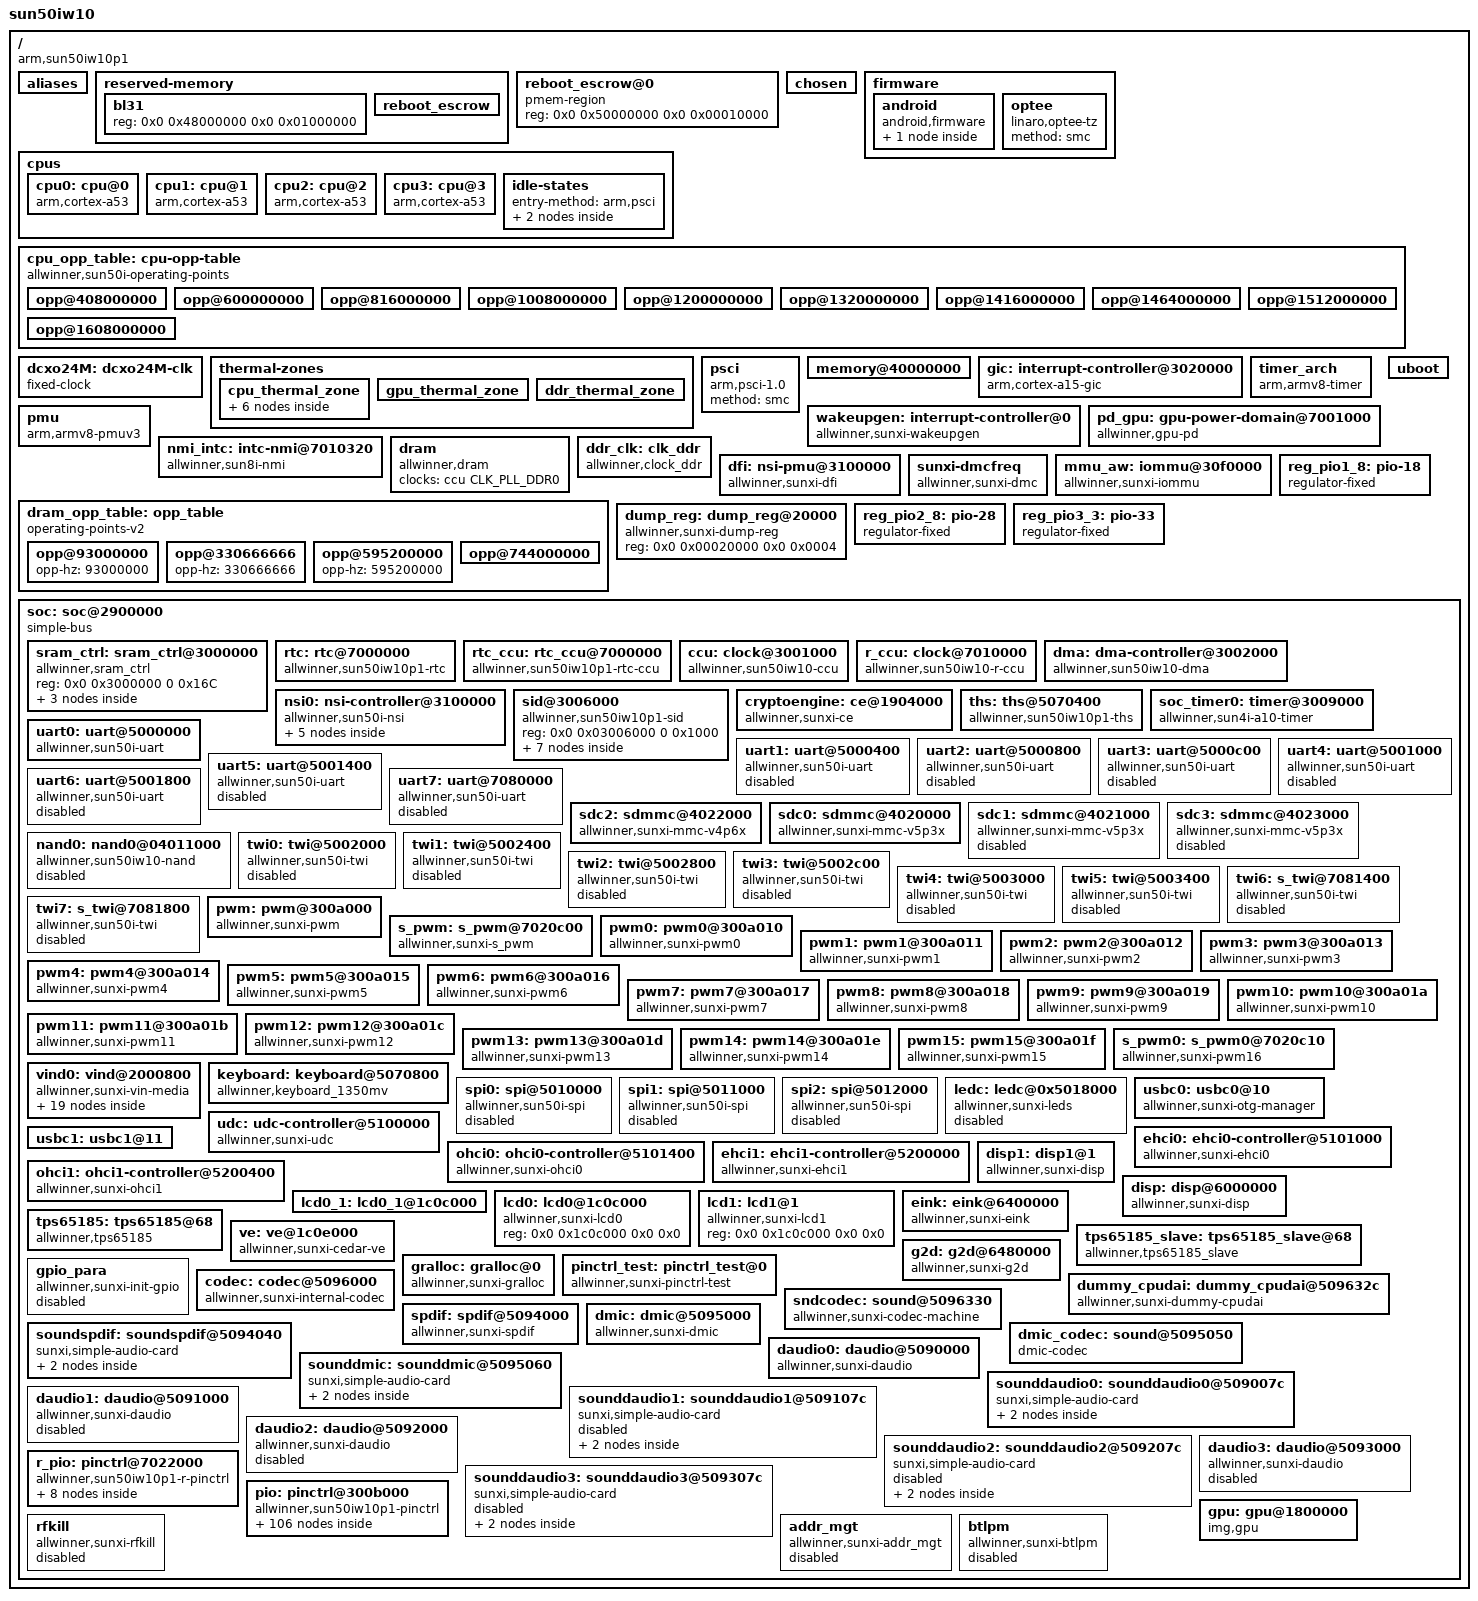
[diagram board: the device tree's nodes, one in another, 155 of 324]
/*
 * Allwinner Technology CO., Ltd. sun50iw10p1 platform
 *
 * modify base on juno.dts
 */

#include <dt-bindings/clock/sun50iw10-ccu.h>
#include <dt-bindings/clock/sun50iw10-r-ccu.h>
#include <dt-bindings/clock/sun50iw10-rtc.h>
#include <dt-bindings/gpio/gpio.h>
#include <dt-bindings/gpio/sun4i-gpio.h>
#include <dt-bindings/interrupt-controller/arm-gic.h>
#include <dt-bindings/reset/sun50iw10-ccu.h>
#include <dt-bindings/reset/sun50iw10-r-ccu.h>
#include <dt-bindings/thermal/thermal.h>

/ {
	model = "sun50iw10";
	compatible = "arm,sun50iw10p1";
	interrupt-parent = <&wakeupgen>;
	#address-cells = <2>;
	#size-cells = <2>;

	aliases {
		serial0 = &uart0;
		serial1 = &uart1;
		serial2 = &uart2;
		serial3 = &uart3;
		serial4 = &uart4;
		serial5 = &uart5;
		serial6 = &uart6;
		serial7 = &uart7;
		lcd0 = &lcd0;
		lcd1 = &lcd1;
		eink = &eink;
		mmc0 = &sdc0;
		mmc2 = &sdc2;
		nand0 =&nand0;
		twi0 = &twi0;
		twi1 = &twi1;
		twi2 = &twi2;
		twi3 = &twi3;
		twi4 = &twi4;
		twi5 = &twi5;
		twi6 = &twi6;
		twi7 = &twi7;
		spi0 = &spi0;
		spi1 = &spi1;
		spi2 = &spi2;
		ledc = &ledc;
		pwm = &pwm;
		s-pwm = &s_pwm;
		pwm0 = &pwm0;
		pwm1 = &pwm1;
		pwm2 = &pwm2;
		pwm3 = &pwm3;
		pwm4 = &pwm4;
		pwm5 = &pwm5;
		pwm6 = &pwm6;
		pwm7 = &pwm7;
		pwm8 = &pwm8;
		pwm9 = &pwm9;
		pwm10 = &pwm10;
		pwm11 = &pwm11;
		pwm12 = &pwm12;
		pwm13 = &pwm13;
		pwm14 = &pwm14;
		pwm15 = &pwm15;
		s-pwm0 = &s_pwm0;
		global-timer0  = &soc_timer0;
		tps65185 = &tps65185;
		tps65185-slave = &tps65185_slave;
	};

	reserved-memory {
		#address-cells = <2>;
		#size-cells = <2>;
		ranges;

		bl31 {
			reg = <0x0 0x48000000 0x0 0x01000000>;
		};
		reboot_escrow {
			no-map;
			reg = <0x0 0x50000000 0x0 0x10000>;
		};
	};

	reboot_escrow@0 {
		compatible = "pmem-region";
		reg = <0x0 0x50000000 0x0 0x00010000>;
	};

	chosen {
		bootargs = "earlyprintk=sunxi-uart,0x05000000 loglevel=8 initcall_debug=0 console=ttyS0 init=/init";
		linux,initrd-start = <0x0 0x0>;
		linux,initrd-end = <0x0 0x0>;
	};

	firmware {
		android {
			compatible = "android,firmware";
			name = "android";
			boot_devices = "soc@2900000/4020000.sdmmc,soc@2900000/4022000.sdmmc,soc@2900000";
			vbmeta {
				compatible = "android,vbmeta";
				parts = "vbmeta,vbmeta_system,vbmeta_vendor,boot";
			};
		};
		optee {
			compatible = "linaro,optee-tz";
			method = "smc";
		};
	};

	cpus {
		#address-cells = <2>;
		#size-cells = <0>;

		cpu0: cpu@0 {
			device_type = "cpu";
			compatible = "arm,cortex-a53","arm,armv8";
			reg = <0x0 0x0>;
			enable-method = "psci";
			clocks = <&ccu CLK_CPUX>;
			clock-latency = <2000000>;
			clock-frequency = <1320000000>;
			dynamic-power-coefficient = <190>;
			operating-points-v2 = <&cpu_opp_table>;
			cpu-idle-states = <&CPU_SLEEP_0 &CLUSTER_SLEEP_0>;
			#cooling-cells = <2>;
		};

		cpu1: cpu@1 {
			device_type = "cpu";
			compatible = "arm,cortex-a53","arm,armv8";
			reg = <0x0 0x1>;
			enable-method = "psci";
			clocks = <&ccu CLK_CPUX>;
			clock-frequency = <1320000000>;
			operating-points-v2 = <&cpu_opp_table>;
			cpu-idle-states = <&CPU_SLEEP_0 &CLUSTER_SLEEP_0>;
			#cooling-cells = <2>;
		};

		cpu2: cpu@2 {
			device_type = "cpu";
			compatible = "arm,cortex-a53","arm,armv8";
			reg = <0x0 0x2>;
			enable-method = "psci";
			clocks = <&ccu CLK_CPUX>;
			clock-frequency = <1320000000>;
			operating-points-v2 = <&cpu_opp_table>;
			cpu-idle-states = <&CPU_SLEEP_0 &CLUSTER_SLEEP_0>;
			#cooling-cells = <2>;
		};

		cpu3: cpu@3 {
			device_type = "cpu";
			compatible = "arm,cortex-a53","arm,armv8";
			reg = <0x0 0x3>;
			enable-method = "psci";
			clocks = <&ccu CLK_CPUX>;
			clock-frequency = <1320000000>;
			operating-points-v2 = <&cpu_opp_table>;
			cpu-idle-states = <&CPU_SLEEP_0 &CLUSTER_SLEEP_0>;
			#cooling-cells = <2>;
		};

		idle-states {
			entry-method = "arm,psci";

			CPU_SLEEP_0: cpu-sleep-0 {
				compatible = "arm,idle-state";
				arm,psci-suspend-param = <0x0010000>;
				entry-latency-us = <46>;
				exit-latency-us = <59>;
				min-residency-us = <3570>;
				local-timer-stop;
			};

			CLUSTER_SLEEP_0: cluster-sleep-0 {
				compatible = "arm,idle-state";
				arm,psci-suspend-param = <0x1010000>;
				entry-latency-us = <47>;
				exit-latency-us = <74>;
				min-residency-us = <5000>;
				local-timer-stop;
			};
		};
	};

	cpu_opp_table: cpu-opp-table {
		compatible = "allwinner,sun50i-operating-points";
		nvmem-cells = <&speedbin_efuse>, <&cpubin_efuse>, <&cpubin_extend>;
		nvmem-cell-names = "speed", "bin", "bin_ext";
		opp-shared;

		opp@408000000 {
			opp-hz = /bits/ 64 <408000000>;
			clock-latency-ns = <244144>; /* 8 32k periods */
			opp-microvolt-a0 = <900000>;
			opp-microvolt-a1 = <900000>;
			opp-microvolt-a2 = <900000>;
			opp-microvolt-a3 = <940000>;
			opp-microvolt-a4 = <940000>;
			opp-microvolt-a5 = <920000>;
			opp-microvolt-a6 = <920000>;
			opp-microvolt-b0 = <900000>;
			opp-microvolt-b1 = <900000>;
			opp-microvolt-b2 = <940000>;
			opp-microvolt-b3 = <920000>;
			opp-supported-hw = <0x7>;
		};

		opp@600000000 {
			opp-hz = /bits/ 64 <600000000>;
			clock-latency-ns = <244144>; /* 8 32k periods */
			opp-microvolt-a0 = <900000>;
			opp-microvolt-a1 = <900000>;
			opp-microvolt-a2 = <900000>;
			opp-microvolt-a3 = <940000>;
			opp-microvolt-a4 = <940000>;
			opp-microvolt-a5 = <920000>;
			opp-microvolt-a6 = <920000>;
			opp-microvolt-b0 = <900000>;
			opp-microvolt-b1 = <900000>;
			opp-microvolt-b2 = <940000>;
			opp-microvolt-b3 = <920000>;
			opp-supported-hw = <0x7>;
		};

		opp@816000000 {
			opp-hz = /bits/ 64 <816000000>;
			clock-latency-ns = <244144>; /* 8 32k periods */
			opp-microvolt-a0 = <940000>;
			opp-microvolt-a1 = <900000>;
			opp-microvolt-a2 = <900000>;
			opp-microvolt-a3 = <940000>;
			opp-microvolt-a4 = <940000>;
			opp-microvolt-a5 = <920000>;
			opp-microvolt-a6 = <920000>;
			opp-microvolt-b0 = <900000>;
			opp-microvolt-b1 = <900000>;
			opp-microvolt-b2 = <940000>;
			opp-microvolt-b3 = <920000>;
			opp-supported-hw = <0x7>;
		};

		opp@1008000000 {
			opp-hz = /bits/ 64 <1008000000>;
			clock-latency-ns = <244144>; /* 8 32k periods */
			opp-microvolt-a0 = <1020000>;
			opp-microvolt-a1 = <980000>;
			opp-microvolt-a2 = <950000>;
			opp-microvolt-a3 = <1020000>;
			opp-microvolt-a4 = <960000>;
			opp-microvolt-a5 = <940000>;
			opp-microvolt-a6 = <940000>;
			opp-microvolt-b0 = <980000>;
			opp-microvolt-b1 = <950000>;
			opp-microvolt-b2 = <960000>;
			opp-microvolt-b3 = <940000>;
			opp-supported-hw = <0x7>;
		};

		opp@1200000000 {
			opp-hz = /bits/ 64 <1200000000>;
			clock-latency-ns = <244144>; /* 8 32k periods */
			opp-microvolt-a0 = <1100000>;
			opp-microvolt-a1 = <1020000>;
			opp-microvolt-a2 = <1000000>;
			opp-microvolt-a3 = <1100000>;
			opp-microvolt-a4 = <980000>;
			opp-microvolt-a5 = <960000>;
			opp-microvolt-a6 = <960000>;
			opp-microvolt-b0 = <1020000>;
			opp-microvolt-b1 = <1000000>;
			opp-microvolt-b2 = <980000>;
			opp-microvolt-b3 = <960000>;
			opp-supported-hw = <0x7>;
		};

		opp@1320000000 {
			opp-hz = /bits/ 64 <1320000000>;
			clock-latency-ns = <244144>; /* 8 32k periods */
			opp-microvolt-a0 = <1160000>;
			opp-microvolt-a1 = <1060000>;
			opp-microvolt-a2 = <1030000>;
			opp-microvolt-a3 = <1160000>;
			opp-microvolt-a4 = <1020000>;
			opp-microvolt-a5 = <1000000>;
			opp-microvolt-a6 = <1000000>;
			opp-microvolt-b0 = <1060000>;
			opp-microvolt-b1 = <1030000>;
			opp-microvolt-b2 = <1020000>;
			opp-microvolt-b3 = <1000000>;
			opp-supported-hw = <0x7>;
		};

		opp@1416000000 {
			opp-hz = /bits/ 64 <1416000000>;
			clock-latency-ns = <244144>; /* 8 32k periods */
			opp-microvolt-b0 = <1100000>;
			opp-microvolt-b1 = <1070000>;
			opp-microvolt-b2 = <1060000>;
			opp-microvolt-b3 = <1040000>;
			opp-supported-hw = <0x6>;
		};

		opp@1464000000 {
			opp-hz = /bits/ 64 <1464000000>;
			clock-latency-ns = <244144>; /* 8 32k periods */
			opp-microvolt-a0 = <1180000>;
			opp-microvolt-a1 = <1180000>;
			opp-microvolt-a2 = <1130000>;
			opp-microvolt-a3 = <1180000>;
			opp-microvolt-a4 = <1100000>;
			opp-microvolt-a5 = <1080000>;
			opp-microvolt-a6 = <1080000>;
			opp-supported-hw = <0x1>;
		};

		opp@1512000000 {
			opp-hz = /bits/ 64 <1512000000>;
			clock-latency-ns = <244144>; /* 8 32k periods */
			opp-microvolt-b0 = <1180000>;
			opp-microvolt-b1 = <1130000 1130000 1140000>;
			opp-microvolt-b2 = <1100000>;
			opp-microvolt-b3 = <1080000>;
			opp-supported-hw = <0x6>;
		};

		opp@1608000000 {
			opp-hz = /bits/ 64 <1608000000>;
			clock-latency-ns = <244144>; /* 8 32k periods */
			opp-microvolt-b0 = <1180000>;
			opp-microvolt-b1 = <1130000 1130000 1140000>;
			opp-supported-hw = <0x0>;
		};
	};

	dcxo24M: dcxo24M-clk {
		#clock-cells = <0>;
		compatible = "fixed-clock";
		clock-frequency = <24000000>;
		clock-output-names = "dcxo24M";
	};

	thermal-zones {
		cpu_thermal_zone {
			polling-delay-passive = <500>;
			polling-delay = <1000>;
			thermal-sensors = <&ths 0>;
			sustainable-power = <1200>;

			cpu_trips: trips {
				cpu_threshold: trip-point@0 {
					temperature = <70000>;
					type = "passive";
					hysteresis = <0>;
				};
				cpu_target: trip-point@1 {
					temperature = <90000>;
					type = "passive";
					hysteresis = <0>;
				};
				cpu_crit: cpu_crit@0 {
					temperature = <110000>;
					type = "critical";
					hysteresis = <0>;
				};
			};

			cooling-maps {
				map0 {
					trip = <&cpu_target>;
					cooling-device = <&cpu0
					THERMAL_NO_LIMIT
					THERMAL_NO_LIMIT>;
					contribution = <1024>;
				};
			};
		};
		gpu_thermal_zone{
			polling-delay-passive = <500>;
			polling-delay = <1000>;
			thermal-sensors = <&ths 1>;
			sustainable-power = <1100>;
		};
		ddr_thermal_zone{
			polling-delay-passive = <0>;
			polling-delay = <0>;
			thermal-sensors = <&ths 2>;
		};
	};

	psci {
		compatible = "arm,psci-1.0";
		method = "smc";
	};

	memory@40000000 {
		device_type = "memory";
		reg = <0x00000000 0x40000000 0x00000000 0x20000000>;
	};

	gic: interrupt-controller@3020000 {
		compatible = "arm,cortex-a15-gic", "arm,cortex-a9-gic";
		#interrupt-cells = <3>;
		#address-cells = <0>;
		device_type = "gic";
		interrupt-controller;
		reg = <0x0 0x03021000 0 0x1000>, /* GIC Dist */
		      <0x0 0x03022000 0 0x2000>, /* GIC CPU */
		      <0x0 0x03024000 0 0x2000>, /* GIC VCPU Control */
		      <0x0 0x03026000 0 0x2000>; /* GIC VCPU */
		interrupts = <GIC_PPI 9 0xf04>;  /* GIC Maintenence IRQ */
		interrupt-parent = <&gic>;
	};

	wakeupgen: interrupt-controller@0 {
		compatible = "allwinner,sunxi-wakeupgen";
		interrupt-controller;
		#interrupt-cells = <3>;
		interrupt-parent = <&gic>;
	};

	timer_arch {
		compatible = "arm,armv8-timer";
		interrupts = <GIC_PPI 13 (GIC_CPU_MASK_SIMPLE(4) | IRQ_TYPE_LEVEL_LOW)>,
			   <GIC_PPI 14 (GIC_CPU_MASK_SIMPLE(4) | IRQ_TYPE_LEVEL_LOW)>,
			   <GIC_PPI 11 (GIC_CPU_MASK_SIMPLE(4) | IRQ_TYPE_LEVEL_LOW)>,
			   <GIC_PPI 10 (GIC_CPU_MASK_SIMPLE(4) | IRQ_TYPE_LEVEL_LOW)>;
		clock-frequency = <24000000>;
		interrupt-parent = <&gic>;
		arm,no-tick-in-suspend;
	};

	pmu {
		compatible = "arm,armv8-pmuv3";
		interrupts = <GIC_SPI 140 IRQ_TYPE_LEVEL_HIGH>,
			     <GIC_SPI 141 IRQ_TYPE_LEVEL_HIGH>,
			     <GIC_SPI 142 IRQ_TYPE_LEVEL_HIGH>,
			     <GIC_SPI 143 IRQ_TYPE_LEVEL_HIGH>;
		interrupt-affinity = <&cpu0>, <&cpu1>, <&cpu2>, <&cpu3>;
	};

	pd_gpu: gpu-power-domain@7001000 {
		   compatible = "allwinner,gpu-pd", "syscon";
		   reg = <0x0 0x07001000 0x0 0x40>;
		   interrupts = <GIC_SPI 119 IRQ_TYPE_LEVEL_HIGH>;
		   interrupt-names = "ppu-irq";
		   clocks = <&r_ccu CLK_R_APB1_PPU>;
		   clock-names = "ppu";
		   resets = <&r_ccu RST_R_APB1_PPU>;
		   reset-names = "ppu_rst";
		   #power-domain-cells = <0>;
	};

	nmi_intc: intc-nmi@7010320 {
		compatible = "allwinner,sun8i-nmi";
		interrupt-parent = <&gic>;
		#interrupt-cells = <2>;
		#address-cells = <0>;
		interrupt-controller;
		reg = <0x0 0x07010320 0 0xc>;
		interrupts = <GIC_SPI 103 IRQ_TYPE_LEVEL_HIGH>;
	};

	dram: dram {
		compatible = "allwinner,dram";
		clocks = <&ccu CLK_PLL_DDR0>;
		clock-names = "pll_ddr";
	};

	ddr_clk: clk_ddr {
		compatible = "allwinner,clock_ddr";
		reg = <0x0 0x03001000 0x0 0x1000>, /*  */
			  <0x0 0x04810000 0x0 0x2000>;
		clocks = <&ccu CLK_PLL_DDR0>;
		clock-names = "pll_ddr";
		#clock-cells = <0>;
	};

	dfi: nsi-pmu@3100000 {
		compatible = "allwinner,sunxi-dfi", "syscon";
		reg = <0x0 0x03100000 0x0 0x10000>;
		clocks = <&ddr_clk>;
		clock-names = "dram";
	};

	dram_opp_table: opp_table {
		compatible = "operating-points-v2";

		opp@93000000 {
			opp-hz = /bits/ 64 <93000000>;
		};
		opp@330666666 {
			opp-hz = /bits/ 64 <330666666>;
		};
		opp@595200000 {
			opp-hz = /bits/ 64 <595200000>;
		};
		opp@744000000 {
			opp-hz = /bits/ 64 <744000000>;
			opp-suspend;
		};
	};

	sunxi-dmcfreq {
		compatible = "allwinner,sunxi-dmc";
		devfreq-events = <&dfi>;
		clocks = <&ddr_clk>;
		clock-names = "dram";
		operating-points-v2 = <&dram_opp_table>;
		upthreshold = <60>;
		downdifferential = <20>;
	};

	uboot: uboot {
	};

	mmu_aw: iommu@30f0000 {
		compatible = "allwinner,sunxi-iommu";
		reg = <0x0 0x030f0000 0x0 0x1000>;
		interrupts = <GIC_SPI 66 IRQ_TYPE_LEVEL_HIGH>;
		interrupt-names = "iommu-irq";
		clocks = <&ccu CLK_BUS_IOMMU>;
		clock-names = "iommu";
		/* clock-frequency = <24000000>; */
		#iommu-cells = <2>;
	};

	dump_reg: dump_reg@20000 {
		compatible = "allwinner,sunxi-dump-reg";
		reg = <0x0 0x00020000 0x0 0x0004>;
		/* 0x00020000 is the addr for test, 0x0004 is the size for test */
	};

	reg_pio1_8: pio-18 {
		compatible = "regulator-fixed";
		regulator-name = "pio-18";
		regulator-min-microvolt = <1800000>;
		regulator-max-microvolt = <1800000>;
	};

	reg_pio2_8: pio-28 {
		compatible = "regulator-fixed";
		regulator-name = "pio-28";
		regulator-min-microvolt = <2800000>;
		regulator-max-microvolt = <2800000>;
	};

	reg_pio3_3: pio-33 {
		compatible = "regulator-fixed";
		regulator-name = "pio-33";
		regulator-min-microvolt = <3300000>;
		regulator-max-microvolt = <3300000>;
	};

	soc: soc@2900000 {
		compatible = "simple-bus";
		#address-cells = <2>;
		#size-cells = <2>;
		ranges;
		device_type = "soc";

		sram_ctrl: sram_ctrl@3000000 {
			compatible = "allwinner,sram_ctrl";
			reg = <0x0 0x3000000 0 0x16C>;
			soc_ver {
				offset = <0x24>;
				mask = <0x7>;
				shift = <0>;
				ver_a = <0x18550000>;
				ver_b = <0x18550001>;
			};

			soc_id {
				offset = <0x200>;
				mask = <0x1>;
				shift = <22>;
			};

			soc_bin {
				offset = <0x0>;
				mask = <0x3ff>;
				shift = <0x0>;
			};

		};

		rtc: rtc@7000000 {
			compatible = "allwinner,sun50iw10p1-rtc";
			device_type = "rtc";
			wakeup-source;
			reg = <0x0 0x07000000 0x0 0x200>;
			interrupts = <GIC_SPI 108 IRQ_TYPE_LEVEL_HIGH>;
			clocks = <&r_ccu CLK_R_AHB_BUS_RTC>, <&rtc_ccu CLK_RTC_1K>;
			clock-names = "r-ahb-rtc", "rtc-1k";
			resets = <&r_ccu RST_R_AHB_BUS_RTC>;
			gpr_offset = <0x100>;
			gpr_len = <8>;
			gpr_cur_pos = <6>;
		};

		rtc_ccu: rtc_ccu@7000000 {
			compatible = "allwinner,sun50iw10p1-rtc-ccu";
			device_type = "rtc-ccu";
			reg = <0x0 0x07000000 0x0 0x200>;
			#clock-cells = <1>;
			clock-output-names = "dcxo24M-out", "iosc", "osc32k",
					     "osc32k-out", "rtc-1k";
		};
		ccu: clock@3001000 {
			compatible = "allwinner,sun50iw10-ccu";
			reg = <0x0 0x03001000 0x0 0x1000>;
			clocks = <&dcxo24M>, <&rtc_ccu CLK_OSC32K>,
				 <&rtc_ccu CLK_IOSC>;
			clock-names = "hosc", "losc", "iosc";
			#clock-cells = <1>;
			#reset-cells = <1>;
		};

		r_ccu: clock@7010000 {
			compatible = "allwinner,sun50iw10-r-ccu";
			reg = <0x0 0x07010000 0x0 0x240>;
			clocks = <&dcxo24M>, <&rtc_ccu CLK_OSC32K>,
				 <&rtc_ccu CLK_IOSC>, <&ccu CLK_PLL_PERIPH0>;
			clock-names = "hosc", "losc", "iosc", "pll-periph";
			#clock-cells = <1>;
			#reset-cells = <1>;
		};

		dma: dma-controller@3002000 {
			compatible = "allwinner,sun50iw10-dma";
			reg = <0x0 0x03002000 0x0 0x1000>;
			interrupts = <GIC_SPI 45 IRQ_TYPE_LEVEL_HIGH>;
			clocks = <&ccu CLK_BUS_DMA>, <&ccu CLK_MBUS_DMA>;
			clock-names = "bus", "mbus";
			dma-channels = <8>;
			dma-requests = <52>;
			resets = <&ccu RST_BUS_DMA>;
			#dma-cells = <1>;
		};

		nsi0:nsi-controller@3100000 {
			compatible = "allwinner,sun50i-nsi";
			interrupts = <GIC_SPI 63 IRQ_TYPE_LEVEL_HIGH>;
			reg = <0x0 0x03100000 0x0 0x10000>;
			clocks = <&ccu CLK_PLL_DDR0>, <&ccu CLK_MBUS>, <&ddr_clk>;
			clock-names = "pll", "bus", "sdram";
			resets = <&ccu RST_MBUS>;
			clock-frequency = <372000000>;
			#nsi-cells = <1>;
			cpu{
				mode = <0>; /*dont't set cpu mode*/
				pri = <0>;
				select = <0>;
			};
			gpu{
				mode = <0>;
				pri = <3>;
				select = <1>;
			};
			sd1{
				mode = <1>;
				pri = <2>;
				select = <0>;
			};
			mstg{
				mode = <0>;
				pri = <1>;
				select = <0>;
			};
			ce{
				mode = <1>;
				pri = <0>;
				select = <1>;
			};
		};

		sid@3006000 {
			compatible = "allwinner,sun50iw10p1-sid", "allwinner,sunxi-sid";
			reg = <0x0 0x03006000 0 0x1000>;
			#address-cells = <1>;
			#size-cells = <1>;

			speedbin_efuse: speed@00 {
				reg = <0x0 2>;
			};

			ths_calib: calib@14 {
				reg = <0x14 8>;
			};

			cpubin_efuse: calib@1c {
				reg = <0x1c 2>;
			};

			cpubin_extend: calib@28 {
				reg = <0x28 4>;
			};

			/* some guys has nothing to do with nvmem */
			secure_status {
				reg = <0x0 0>;
				offset = <0xa0>;
				size = <0x4>;
			};
			chipid {
				reg = <0x0 0>;
				offset = <0x200>;
				size = <0x10>;
			};
			rotpk {
				reg = <0x0 0>;
				offset = <0x270>;
				size = <0x20>;
			};
		};

		cryptoengine: ce@1904000 {
			compatible = "allwinner,sunxi-ce";
			device_name = "ce";
			reg = <0x0 0x01904000 0x0 0xa0>, /* non-secure space */
			      <0x0 0x01904800 0x0 0xa0>; /* secure space */
			interrupts = <GIC_SPI 92 IRQ_TYPE_EDGE_RISING>, /*non-secure*/
				   <GIC_SPI 93 IRQ_TYPE_EDGE_RISING>; /* secure*/
			clock-frequency = <400000000>; /* 400MHz */
			clocks = <&ccu CLK_BUS_CE>, <&ccu CLK_CE>, <&ccu CLK_MBUS_CE>,
					<&ccu CLK_PLL_PERIPH0_2X>;
			clock-names = "bus_ce", "ce_clk", "mbus_ce", "pll_periph0_2x";
			resets = <&ccu RST_BUS_CE>;
		};

		ths: ths@5070400 {
			compatible = "allwinner,sun50iw10p1-ths";
			reg = <0x0 0x05070400 0x0 0x400>;
			clocks = <&ccu CLK_BUS_THS>;
			clock-names = "bus";
			resets = <&ccu RST_BUS_THS>;
			nvmem-cells = <&ths_calib>;
			nvmem-cell-names = "calibration";
			#thermal-sensor-cells = <1>;
		};

		soc_timer0: timer@3009000 {
			compatible = "allwinner,sun4i-a10-timer";
			device_type = "soc_timer";
			reg = <0x0 0x03009000 0x0 0xA0>;
			interrupt-parent = <&gic>;
			interrupts = <GIC_SPI 51 IRQ_TYPE_LEVEL_HIGH>;
			clocks = <&dcxo24M>;
		};

		uart0: uart@5000000 {
			compatible = "allwinner,sun50i-uart";
			device_type = "uart0";
			reg = <0x0 0x05000000 0x0 0x400>;
			interrupts = <GIC_SPI 0 IRQ_TYPE_LEVEL_HIGH>;
			sunxi,uart-fifosize = <64>;
			clocks = <&ccu CLK_BUS_UART0>;
			clock-names = "uart0";
			resets = <&ccu RST_BUS_UART0>;
			pinctrl-names = "default", "sleep";
			pinctrl-0 = <&uart0_pins_a>;
			pinctrl-1 = <&uart0_pins_b>;
			uart0_port = <0>;
			uart0_type = <2>;
			//dmas = <&dma 14>;
			//dma-names = "tx";
			//use_dma = <0>;
		};

		uart1: uart@5000400 {
			compatible = "allwinner,sun50i-uart";
			device_type = "uart1";
			reg = <0x0 0x05000400 0x0 0x400>;
			interrupts = <GIC_SPI 1 IRQ_TYPE_LEVEL_HIGH>;
			sunxi,uart-fifosize = <64>;
			clocks = <&ccu CLK_BUS_UART1>;
			clock-names = "uart1";
			resets = <&ccu RST_BUS_UART1>;
			pinctrl-names = "default", "sleep";
			pinctrl-0 = <&uart1_pins_a>;
			pinctrl-1 = <&uart1_pins_b>;
			uart1_port = <1>;
			uart1_type = <4>;
			status = "disabled";
		};

		uart2: uart@5000800 {
			compatible = "allwinner,sun50i-uart";
			device_type = "uart2";
			reg = <0x0 0x05000800 0x0 0x400>;
			interrupts = <GIC_SPI 2 IRQ_TYPE_LEVEL_HIGH>;
			sunxi,uart-fifosize = <64>;
			clocks = <&ccu CLK_BUS_UART2>;
			clock-names = "uart2";
			resets = <&ccu RST_BUS_UART2>;
			pinctrl-names = "default", "sleep";
			pinctrl-0 = <&uart2_pins_a>;
			pinctrl-1 = <&uart2_pins_b>;
			uart2_port = <2>;
			uart2_type = <4>;
			status = "disabled";
		};

		uart3: uart@5000c00 {
			compatible = "allwinner,sun50i-uart";
			device_type = "uart3";
			reg = <0x0 0x05000c00 0x0 0x400>;
			interrupts = <GIC_SPI 3 IRQ_TYPE_LEVEL_HIGH>;
			sunxi,uart-fifosize = <64>;
			clocks = <&ccu CLK_BUS_UART3>;
			clock-names = "uart3";
			resets = <&ccu RST_BUS_UART3>;
			pinctrl-names = "default", "sleep";
			pinctrl-0 = <&uart3_pins_a>;
			pinctrl-1 = <&uart3_pins_b>;
			uart3_port = <3>;
			uart3_type = <4>;
			status = "disabled";
		};

		uart4: uart@5001000 {
			compatible = "allwinner,sun50i-uart";
			device_type = "uart4";
			reg = <0x0 0x05001000 0x0 0x400>;
			interrupts = <GIC_SPI 4 IRQ_TYPE_LEVEL_HIGH>;
			clocks = <&ccu CLK_BUS_UART4>;
			clock-names = "uart4";
			resets = <&ccu RST_BUS_UART4>;
			sunxi,uart-fifosize = <64>;
			pinctrl-names = "default", "sleep";
			pinctrl-0 = <&uart4_pins_a>;
			pinctrl-1 = <&uart4_pins_b>;
			uart4_port = <4>;
			uart4_type = <4>;
			status = "disabled";
		};

		uart5: uart@5001400 {
			compatible = "allwinner,sun50i-uart";
			device_type = "uart5";
			reg = <0x0 0x05001400 0x0 0x400>;
			interrupts = <GIC_SPI 5 IRQ_TYPE_LEVEL_HIGH>;
			sunxi,uart-fifosize = <64>;
			clocks = <&ccu CLK_BUS_UART5>;
			clock-names = "uart5";
			resets = <&ccu RST_BUS_UART5>;
			pinctrl-names = "default", "sleep";
			pinctrl-0 = <&uart5_pins_a>;
			pinctrl-1 = <&uart5_pins_b>;
			uart5_port = <5>;
			uart5_type = <4>;
			status = "disabled";
		};

		uart6: uart@5001800 {
			compatible = "allwinner,sun50i-uart";
			device_type = "uart6";
			reg = <0x0 0x05001800 0x0 0x400>;
			interrupts = <GIC_SPI 6 IRQ_TYPE_LEVEL_HIGH>;
			sunxi,uart-fifosize = <64>;
			/* fix me */
			/*clocks = <&ccu CLK_BUS_UART6>;
			clock-names = "uart6";
			resets = <&ccu RST_BUS_UART6>;*/
			pinctrl-names = "default", "sleep";
			pinctrl-0 = <&uart6_pins_a>;
			pinctrl-1 = <&uart6_pins_b>;
			uart6_port = <6>;
			uart6_type = <4>;
			status = "disabled";
		};

		uart7: uart@7080000 {
			compatible = "allwinner,sun50i-uart";
			device_type = "uart7";
			reg = <0x0 0x07080000 0x0 0x400>;
			interrupts = <GIC_SPI 112 IRQ_TYPE_LEVEL_HIGH>;
			sunxi,uart-fifosize = <64>;
			/* fix me */
			/*clocks = <&r_ccu CLK_BUS_UART0>;
			clock-names = "uart7";
			resets = <&r_ccu RST_BUS_UART0>;*/
			pinctrl-names = "default", "sleep";
			pinctrl-0 = <&s_uart0_pins_a>;
			pinctrl-1 = <&s_uart0_pins_b>;
			uart7_port = <7>;
			uart7_type = <2>;
			status = "disabled";
		};

		sdc2: sdmmc@4022000 {
			compatible = "allwinner,sunxi-mmc-v4p6x";
			device_type = "sdc2";
			reg = <0x0 0x04022000 0x0 0x1000>;
			interrupts = <GIC_SPI 41 IRQ_TYPE_LEVEL_HIGH>;
			clocks = <&dcxo24M>,
				 <&ccu CLK_PLL_PERIPH1_2X>,
				 <&ccu CLK_MMC2>,
				 <&ccu CLK_BUS_MMC2>;
			clock-names = "osc24m","pll_periph","mmc","ahb";
			resets = <&ccu RST_BUS_MMC2>;
			reset-names = "rst";
			pinctrl-names = "default","sleep";
			pinctrl-0 = <&sdc2_pins_a &sdc2_pins_c>;
			pinctrl-1 = <&sdc2_pins_b>;
			bus-width = <8>;
			req-page-count = <2>;
			cap-mmc-highspeed;
			cap-cmd23;
			mmc-cache-ctrl;
			non-removable;
			/*max-frequency = <200000000>;*/
			max-frequency = <50000000>;
			cap-erase;
			mmc-high-capacity-erase-size;
			no-sdio;
			no-sd;
			/*-- speed mode --*/
			/*sm0: DS26_SDR12*/
			/*sm1: HSSDR52_SDR25*/
			/*sm2: HSDDR52_DDR50*/
			/*sm3: HS200_SDR104*/
			/*sm4: HS400*/
			/*-- frequency point --*/
			/*f0: CLK_400K*/
			/*f1: CLK_25M*/
			/*f2: CLK_50M*/
			/*f3: CLK_100M*/
			/*f4: CLK_150M*/
			/*f5: CLK_200M*/

			sdc_tm4_sm0_freq0 = <0>;
			sdc_tm4_sm0_freq1 = <0>;
			sdc_tm4_sm1_freq0 = <0x00000000>;
			sdc_tm4_sm1_freq1 = <0>;
			sdc_tm4_sm2_freq0 = <0x00000000>;
			sdc_tm4_sm2_freq1 = <0>;
			sdc_tm4_sm3_freq0 = <0x05000000>;
			sdc_tm4_sm3_freq1 = <0x00000005>;
			sdc_tm4_sm4_freq0 = <0x00050000>;
			sdc_tm4_sm4_freq1 = <0x00000004>;
			sdc_tm4_sm4_freq0_cmd = <0>;
			sdc_tm4_sm4_freq1_cmd = <0>;

			/*vmmc-supply = <&reg_3p3v>;*/
			/*vqmc-supply = <&reg_3p3v>;*/
			/*vdmc-supply = <&reg_3p3v>;*/
			/*vmmc = "vcc-card";*/
			/*vqmc = "";*/
			/*vdmc = "";*/
			/*sunxi-power-save-mode;*/
		};

		sdc0: sdmmc@4020000 {
			compatible = "allwinner,sunxi-mmc-v5p3x";
			device_type = "sdc0";
			reg = <0x0 0x04020000 0x0 0x1000>;
			interrupts = <GIC_SPI 39 IRQ_TYPE_LEVEL_HIGH>;
			clocks = <&dcxo24M>,
				 <&ccu CLK_PLL_PERIPH1_2X>,
				 <&ccu CLK_MMC0>,
				 <&ccu CLK_BUS_MMC0>;
			clock-names = "osc24m","pll_periph","mmc","ahb";
			resets = <&ccu RST_BUS_MMC0>;
			reset-names = "rst";
			pinctrl-names = "default","mmc_1v8","sleep","uart_jtag";
			pinctrl-0 = <&sdc0_pins_a>;
			pinctrl-1 = <&sdc0_pins_b>;
			pinctrl-2 = <&sdc0_pins_c>;
			pinctrl-3 = <&sdc0_pins_d &sdc0_pins_e>;
			max-frequency = <50000000>;
			bus-width = <4>;
			req-page-count = <2>;
			/*non-removable;*/
			/*broken-cd;*/
			/*cd-inverted*/
			/*cd-gpios = <&pio PF 6 GPIO_ACTIVE_LOW>;*/
			/* vmmc-supply = <&reg_3p3v>;*/
			/* vqmc-supply = <&reg_3p3v>;*/
			/* vdmc-supply = <&reg_3p3v>;*/
			/*vmmc = "vcc-card";*/
			/*vqmc = "";*/
			/*vdmc = "";*/
			cap-sd-highspeed;
			cap-wait-while-busy;
			no-sdio;
			no-mmc;
			/*sd-uhs-sdr50;*/
			/*sd-uhs-ddr50;*/
			/*cap-sdio-irq;*/
			/*keep-power-in-suspend;*/
			/*ignore-pm-notify;*/
			/*sunxi-power-save-mode;*/
			/*sunxi-dly-400k = <1 0 0 0>; */
			/*sunxi-dly-26M  = <1 0 0 0>;*/
			/*sunxi-dly-52M  = <1 0 0 0>;*/
			/*sunxi-dly-52M-ddr4  = <1 0 0 0>;*/
			/*sunxi-dly-52M-ddr8  = <1 0 0 0>;*/
			/*sunxi-dly-104M  = <1 0 0 0>;*/
			/*sunxi-dly-208M  = <1 0 0 0>;*/
			/*sunxi-dly-104M-ddr  = <1 0 0 0>;*/
			/*sunxi-dly-208M-ddr  = <1 0 0 0>;*/
		};

		sdc1: sdmmc@4021000 {
			compatible = "allwinner,sunxi-mmc-v5p3x";
			device_type = "sdc1";
			reg = <0x0 0x04021000 0x0 0x1000>;
			interrupts = <GIC_SPI 40 IRQ_TYPE_LEVEL_HIGH>;
			clocks = <&dcxo24M>,
				 <&ccu CLK_PLL_PERIPH1_2X>,
				 <&ccu CLK_MMC1>,
				 <&ccu CLK_BUS_MMC1>;
			clock-names = "osc24m","pll_periph","mmc","ahb";
			resets = <&ccu RST_BUS_MMC1>;
			reset-names = "rst";
			pinctrl-names = "default","sleep";
			pinctrl-0 = <&sdc1_pins_a>;
			pinctrl-1 = <&sdc1_pins_b>;
			max-frequency = <50000000>;
			bus-width = <4>;
			/*broken-cd;*/
			/*cd-inverted*/
			/*cd-gpios = <&pio PG 6 6 1 2 0>;*/
			/* vmmc-supply = <&reg_3p3v>;*/
			/* vqmc-supply = <&reg_3p3v>;*/
			/* vdmc-supply = <&reg_3p3v>;*/
			/*vmmc = "vcc-card";*/
			/*vqmc = "";*/
			/*vdmc = "";*/
			cap-sd-highspeed;
			no-mmc;
			/*sd-uhs-sdr50;*/
			/*sd-uhs-ddr50;*/
			/*sd-uhs-sdr104;*/
			/*cap-sdio-irq;*/
			keep-power-in-suspend;
			/*ignore-pm-notify;*/
			/*sunxi-power-save-mode;*/
			/*sunxi-dly-400k = <1 0 0 0 0>; */
			/*sunxi-dly-26M  = <1 0 0 0 0>;*/
			/*sunxi-dly-52M  = <1 0 0 0 0>;*/
			sunxi-dly-52M-ddr4  = <1 0 0 0 2>;
			/*sunxi-dly-52M-ddr8  = <1 0 0 0 0>;*/
			sunxi-dly-104M  = <1 0 0 0 1>;
			/*sunxi-dly-208M  = <1 1 0 0 0>;*/
			sunxi-dly-208M  = <1 0 0 0 1>;
			/*sunxi-dly-104M-ddr  = <1 0 0 0 0>;*/
			/*sunxi-dly-208M-ddr  = <1 0 0 0 0>;*/

			status = "disabled";
		};

		sdc3: sdmmc@4023000 {
			compatible = "allwinner,sunxi-mmc-v5p3x";
			device_type = "sdc3";
			reg = <0x0 0x04023000 0x0 0x1000>;
			interrupts = <GIC_SPI 42 IRQ_TYPE_LEVEL_HIGH>;
			/*the system has not configured sdmmc3 clk*/
			/*clocks = <&clk_hosc>,*/
			/*	 <&clk_pll_periph1x2>,*/
			/*	 <&clk_sdmmc3_mod>,*/
			/*	 <&clk_sdmmc3_bus>,*/
			/*	 <&clk_sdmmc3_rst>;*/
			/*clock-names = "osc24m","pll_periph","mmc","ahb","rst";*/
			pinctrl-names = "default","sleep";
			pinctrl-0 = <&sdc3_pins_a>;
			pinctrl-1 = <&sdc3_pins_b>;
			max-frequency = <50000000>;
			bus-width = <4>;
			cap-sd-highspeed;
			no-sdio;
			no-mmc;
			/*broken-cd;*/
			/*cd-inverted*/
			/*cd-gpios = <&pio PG 6 6 1 2 0>;*/
			/* vmmc-supply = <&reg_3p3v>;*/
			/* vqmc-supply = <&reg_3p3v>;*/
			/* vdmc-supply = <&reg_3p3v>;*/
			/*vmmc = "vcc-card";*/
			/*vqmc = "";*/
			/*vdmc = "";*/
			/*sd-uhs-sdr50;*/
			/*sd-uhs-ddr50;*/
			/*sd-uhs-sdr104;*/
			/*cap-sdio-irq;*/
			/*keep-power-in-suspend;*/
			/*ignore-pm-notify;*/
			/*sunxi-power-save-mode;*/
			/*sunxi-dly-400k = <1 0 0 0 0>; */
			/*sunxi-dly-26M  = <1 0 0 0 0>;*/
			/*sunxi-dly-52M  = <1 0 0 0 0>;*/
			/*sunxi-dly-52M-ddr8  = <1 0 0 0 0>;*/
			/*sunxi-dly-208M  = <1 1 0 0 0>;*/
			/*sunxi-dly-104M-ddr  = <1 0 0 0 0>;*/
			/*sunxi-dly-208M-ddr  = <1 0 0 0 0>;*/

			status = "disabled";
		};

		nand0:nand0@04011000 {
			compatible = "allwinner,sun50iw10-nand";
			device_type = "nand0";
			reg = <0x0 0x04011000 0x0 0x1000>;/* nand0 */
			interrupts = <GIC_SPI 38 IRQ_TYPE_LEVEL_HIGH>;
			clocks = <&ccu CLK_PLL_PERIPH1_2X>,
				<&ccu CLK_NAND0>,
				 <&ccu CLK_NAND1>,
				 <&ccu CLK_BUS_NAND>,
				 <&ccu CLK_MBUS_NAND>;
			clock-names = "pll_periph","mclk","ecc", "bus", "mbus";
			resets = <&ccu RST_BUS_NAND>;
			reset-names = "rst";

			pinctrl-names = "default", "sleep";
			pinctrl-0 = <&nand0_pins_a &nand0_pins_b>;
			pinctrl-1 = <&nand0_pins_c>;

			nand0_regulator1 = "none";
			nand0_regulator2 = "none";
			nand0_cache_level = <0x55aaaa55>;
			nand0_flush_cache_num = <0x55aaaa55>;
			nand0_capacity_level = <0x55aaaa55>;
			nand0_id_number_ctl = <0x55aaaa55>;
			nand0_print_level = <0x55aaaa55>;
			nand0_p0 = <0x55aaaa55>;
			nand0_p1 = <0x55aaaa55>;
			nand0_p2 = <0x55aaaa55>;
			nand0_p3 = <0x55aaaa55>;
			chip_code = "sun50iw10";
			status = "disabled";
		};

		twi0: twi@5002000{
			#address-cells = <1>;
			#size-cells = <0>;
			compatible = "allwinner,sun50i-twi";
			device_type = "twi0";
			reg = <0x0 0x05002000 0x0 0x400>;
			interrupts = <GIC_SPI 7 IRQ_TYPE_LEVEL_HIGH>;
			clocks = <&ccu CLK_BUS_I2C0>;
			resets = <&ccu RST_BUS_I2C0>;
			clock-names = "bus";
			clock-frequency = <400000>;
			pinctrl-names = "default", "sleep";
			pinctrl-0 = <&twi0_pins_a>;
			pinctrl-1 = <&twi0_pins_b>;
			status = "disabled";
		};

		twi1: twi@5002400{
			#address-cells = <1>;
			#size-cells = <0>;
			compatible = "allwinner,sun50i-twi";
			device_type = "twi1";
			reg = <0x0 0x05002400 0x0 0x400>;
			interrupts = <GIC_SPI 8 IRQ_TYPE_LEVEL_HIGH>;
			clocks = <&ccu CLK_BUS_I2C1>;
			resets = <&ccu RST_BUS_I2C1>;
			clock-names = "bus";
			clock-frequency = <200000>;
			pinctrl-names = "default", "sleep";
			pinctrl-0 = <&twi1_pins_a>;
			pinctrl-1 = <&twi1_pins_b>;
			status = "disabled";
		};

		twi2: twi@5002800{
			#address-cells = <1>;
			#size-cells = <0>;
			compatible = "allwinner,sun50i-twi";
			device_type = "twi2";
			reg = <0x0 0x05002800 0x0 0x400>;
			interrupts = <GIC_SPI 9 IRQ_TYPE_LEVEL_HIGH>;
			clocks = <&ccu CLK_BUS_I2C2>;
			resets = <&ccu RST_BUS_I2C2>;
			clock-names = "bus";
			clock-frequency = <100000>;
			pinctrl-names = "default", "sleep";
			pinctrl-0 = <&twi2_pins_a>;
			pinctrl-1 = <&twi2_pins_b>;
			status = "disabled";
		};

		twi3: twi@5002c00{
			#address-cells = <1>;
			#size-cells = <0>;
			compatible = "allwinner,sun50i-twi";
			device_type = "twi3";
			reg = <0x0 0x05002c00 0x0 0x400>;
			interrupts = <GIC_SPI 10 IRQ_TYPE_LEVEL_HIGH>;
			clocks = <&ccu CLK_BUS_I2C3>;
			resets = <&ccu RST_BUS_I2C3>;
			clock-names = "bus";
			clock-frequency = <100000>;
			pinctrl-names = "default", "sleep";
			pinctrl-0 = <&twi3_pins_a>;
			pinctrl-1 = <&twi3_pins_b>;
			status = "disabled";
		};

		twi4: twi@5003000{
			#address-cells = <1>;
			#size-cells = <0>;
			compatible = "allwinner,sun50i-twi";
			device_type = "twi4";
			reg = <0x0 0x05003000 0x0 0x400>;
			interrupts = <GIC_SPI 11 IRQ_TYPE_LEVEL_HIGH>;
			clocks = <&ccu CLK_BUS_I2C4>;
			resets = <&ccu RST_BUS_I2C4>;
			clock-names = "bus";
			clock-frequency = <100000>;
			pinctrl-names = "default", "sleep";
			pinctrl-0 = <&twi4_pins_a>;
			pinctrl-1 = <&twi4_pins_b>;
			status = "disabled";
		 };

		twi5: twi@5003400{
			#address-cells = <1>;
			#size-cells = <0>;
			compatible = "allwinner,sun50i-twi";
			device_type = "twi5";
			reg = <0x0 0x05003400 0x0 0x400>;
			interrupts = <GIC_SPI 12 IRQ_TYPE_LEVEL_HIGH>;
			clocks = <&ccu CLK_BUS_I2C5>;
			resets = <&ccu RST_BUS_I2C5>;
			clock-names = "bus";
			clock-frequency = <100000>;
			pinctrl-names = "default", "sleep";
			pinctrl-0 = <&twi5_pins_a>;
			pinctrl-1 = <&twi5_pins_b>;
			status = "disabled";
		};

		twi6: s_twi@7081400 {
			#address-cells = <1>;
			#size-cells = <0>;
			compatible = "allwinner,sun50i-twi";
			reg = <0x0 0x07081400 0x0 0x200>;
			interrupts = <GIC_SPI 113 IRQ_TYPE_LEVEL_HIGH>;
			clocks = <&r_ccu CLK_R_APB2_I2C0>;
			resets = <&r_ccu RST_R_APB2_I2C0>;
			clock-names = "bus";
			clock-frequency = <200000>;
			pinctrl-names = "default", "sleep";
			pinctrl-0 = <&s_twi0_pins_a>;
			status = "disabled";
		};

		twi7: s_twi@7081800 {
			#address-cells = <1>;
			#size-cells = <0>;
			compatible = "allwinner,sun50i-twi";
			reg = <0x0 0x07081800 0x0 0x200>;
			interrupts = <GIC_SPI 114 IRQ_TYPE_LEVEL_HIGH>;
			clocks = <&r_ccu CLK_R_APB2_I2C1>;
			resets = <&r_ccu RST_R_APB2_I2C1>;
			clock-names = "bus";
			clock-frequency = <200000>;
			pinctrl-names = "default", "sleep";
			pinctrl-0 = <&s_twi1_pins_a>;
			status = "disabled";
		};

		pwm: pwm@300a000 {
			#pwm-cells = <0x3>;
			compatible = "allwinner,sunxi-pwm";
			reg = <0x0 0x0300a000 0x0 0x3ff>;
			clocks = <&ccu CLK_BUS_PWM>;
			resets = <&ccu RST_BUS_PWM>;
			pwm-number = <16>;
			pwm-base = <0x0>;
			sunxi-pwms = <&pwm0>, <&pwm1>, <&pwm2>, <&pwm3>, <&pwm4>,
				<&pwm5>, <&pwm6>, <&pwm7>, <&pwm8>, <&pwm9>,
				<&pwm10>, <&pwm11>, <&pwm12>, <&pwm13>,
				<&pwm14>, <&pwm15>;
		};

		s_pwm: s_pwm@7020c00 {
			#pwm-cells = <0x3>;
			compatible = "allwinner,sunxi-s_pwm";
			reg = <0x0 0x07020c00 0x0 0x3ff>;
			clocks = <&r_ccu CLK_R_APB1_PWM>, <&r_ccu CLK_R_APB1_BUS_PWM>;
			resets = <&r_ccu RST_R_APB1_BUS_PWM>;
			pwm-number = <1>;
			pwm-base = <0x10>;
			sunxi-pwms = <&s_pwm0>;
		};

		pwm0: pwm0@300a010 {
			compatible = "allwinner,sunxi-pwm0";
			pinctrl-names = "active", "sleep";
			reg = <0x0 0x0300a010 0x0 0x4>;
			reg_base = <0x0300a000>;
		};

		pwm1: pwm1@300a011 {
			compatible = "allwinner,sunxi-pwm1";
			pinctrl-names = "active", "sleep";
			reg = <0x0 0x0300a011 0x0 0x4>;
			reg_base = <0x0300a000>;
		};

		pwm2: pwm2@300a012 {
			compatible = "allwinner,sunxi-pwm2";
			pinctrl-names = "active", "sleep";
			reg = <0x0 0x0300a012 0x0 0x4>;
			reg_base = <0x0300a000>;
		};

		pwm3: pwm3@300a013 {
			compatible = "allwinner,sunxi-pwm3";
			pinctrl-names = "active", "sleep";
			reg = <0x0 0x0300a013 0x0 0x4>;
			reg_base = <0x0300a000>;
		};

		pwm4: pwm4@300a014 {
			compatible = "allwinner,sunxi-pwm4";
			pinctrl-names = "active", "sleep";
			reg = <0x0 0x0300a014 0x0 0x4>;
			reg_base = <0x0300a000>;
		};

		pwm5: pwm5@300a015 {
			compatible = "allwinner,sunxi-pwm5";
			pinctrl-names = "active", "sleep";
			reg = <0x0 0x0300a015 0x0 0x4>;
			reg_base = <0x0300a000>;
		};

		pwm6: pwm6@300a016 {
			compatible = "allwinner,sunxi-pwm6";
			pinctrl-names = "active", "sleep";
			reg = <0x0 0x0300a016 0x0 0x4>;
			reg_base = <0x0300a000>;
		};

		pwm7: pwm7@300a017 {
			compatible = "allwinner,sunxi-pwm7";
			pinctrl-names = "active", "sleep";
			reg = <0x0 0x0300a017 0x0 0x4>;
			reg_base = <0x0300a000>;
		};

		pwm8: pwm8@300a018 {
			compatible = "allwinner,sunxi-pwm8";
			pinctrl-names = "active", "sleep";
			reg = <0x0 0x0300a018 0x0 0x4>;
			reg_base = <0x0300a000>;
		};

		pwm9: pwm9@300a019 {
			compatible = "allwinner,sunxi-pwm9";
			pinctrl-names = "active", "sleep";
			reg = <0x0 0x0300a019 0x0 0x4>;
			reg_base = <0x0300a000>;
		};

		pwm10: pwm10@300a01a {
			compatible = "allwinner,sunxi-pwm10";
			pinctrl-names = "active", "sleep";
			reg = <0x0 0x0300a01a 0x0 0x4>;
			reg_base = <0x0300a000>;
		};

		pwm11: pwm11@300a01b {
			compatible = "allwinner,sunxi-pwm11";
			pinctrl-names = "active", "sleep";
			reg = <0x0 0x0300a01b 0x0 0x4>;
			reg_base = <0x0300a000>;
		};

		pwm12: pwm12@300a01c {
			compatible = "allwinner,sunxi-pwm12";
			pinctrl-names = "active", "sleep";
			reg = <0x0 0x0300a01c 0x0 0x4>;
			reg_base = <0x0300a000>;
		};

		pwm13: pwm13@300a01d {
			compatible = "allwinner,sunxi-pwm13";
			pinctrl-names = "active", "sleep";
			reg = <0x0 0x0300a01d 0x0 0x4>;
			reg_base = <0x0300a000>;
		};

		pwm14: pwm14@300a01e {
			compatible = "allwinner,sunxi-pwm14";
			pinctrl-names = "active", "sleep";
			reg = <0x0 0x0300a01e 0x0 0x4>;
			reg_base = <0x0300a000>;
		};

		pwm15: pwm15@300a01f {
			compatible = "allwinner,sunxi-pwm15";
			pinctrl-names = "active", "sleep";
			reg = <0x0 0x0300a01f 0x0 0x4>;
			reg_base = <0x0300a000>;
		};

		s_pwm0: s_pwm0@7020c10 {
			compatible = "allwinner,sunxi-pwm16";
			pinctrl-names = "active", "sleep";
			reg = <0x0 0x07020c10 0x0 0x4>;
			reg_base = <0x07020c00>;
		};

		vind0: vind@2000800 {
			compatible = "allwinner,sunxi-vin-media", "simple-bus";
			#address-cells = <2>;
			#size-cells = <2>;
			ranges;
			device_id = <0>;
			csi_top = <336000000>;
			csi_isp = <327000000>;
			reg = <0x0 0x02000800 0x0 0x200>,
				<0x0 0x02000000 0x0 0x800>,
				<0x0 0x0200A000 0x0 0x100>;
			clocks = <&ccu CLK_CSI_TOP>, <&ccu CLK_PLL_VIDEO2_2X>,
				<&ccu CLK_CSI0_MCLK>, <&dcxo24M>, <&ccu CLK_PLL_VIDEO2>,
				<&ccu CLK_CSI1_MCLK>, <&dcxo24M>, <&ccu CLK_PLL_VIDEO2>,
				<&ccu CLK_CSI_ISP>, <&ccu CLK_PLL_VIDEO3_2X>,
				<&ccu CLK_BUS_CSI>, <&ccu CLK_MBUS_CSI>, <&ccu CLK_MBUS_ISP>;
			clock-names = "csi_top", "csi_top_src",
					"csi_mclk0", "csi_mclk0_24m", "csi_mclk0_pll",
					"csi_mclk1", "csi_mclk1_24m", "csi_mclk1_pll",
					"csi_isp", "csi_isp_src",
					"csi_bus", "csi_mbus", "csi_isp_mbus";
			resets = <&ccu RST_BUS_CSI>, <&ccu RST_BUS_CSI_ISP>;
			reset-names = "csi_ret","isp_ret";
			pinctrl-names = "mclk0-default","mclk0-sleep","mclk1-default","mclk1-sleep";
			pinctrl-0 = <&csi_mclk0_pins_a>;
			pinctrl-1 = <&csi_mclk0_pins_b>;
			pinctrl-2 = <&csi_mclk1_pins_a>;
			pinctrl-3 = <&csi_mclk1_pins_b>;

			csi0: csi@2001000 {
				compatible = "allwinner,sunxi-csi";
				reg = <0x0 0x02001000 0x0 0x1000>;
				interrupts = <GIC_SPI 75 IRQ_TYPE_LEVEL_HIGH>;
				device_id = <0>;
				iommus = <&mmu_aw 3 1>;
			};
			csi1: csi@2002000 {
				compatible = "allwinner,sunxi-csi";
				reg = <0x0 0x02002000 0x0 0x1000>;
				interrupts = <GIC_SPI 76 IRQ_TYPE_LEVEL_HIGH>;
				device_id = <1>;
				iommus = <&mmu_aw 3 1>;
			};
			mipi0: mipi@200a100 {
				compatible = "allwinner,sunxi-mipi";
				reg = <0x0 0x0200A100 0x0 0x100>,
					<0x0 0x0200B000 0x0 0x400>;
				interrupts = <GIC_SPI 80 IRQ_TYPE_LEVEL_HIGH>;
				device_id = <0>;
			};
			mipi1: mipi@200a200 {
				compatible = "allwinner,sunxi-mipi";
				reg = <0x0 0x0200A200 0x0 0x100>,
					<0x0 0x0200B400 0x0 0x400>;
				device_id = <1>;
			};
			tdm0: tdm@2108000 {
				compatible = "allwinner,sunxi-tdm";
				reg = <0x0 0x02108000 0x0 0x180>;
				interrupts = <GIC_SPI 79 IRQ_TYPE_LEVEL_HIGH>;
				device_id = <0>;
				iommus = <&mmu_aw 4 1>;
			};
			isp0: isp@2100000 {
				compatible = "allwinner,sunxi-isp";
				reg = <0x0 0x02100000 0x0 0x2000>;
				interrupts = <GIC_SPI 77 IRQ_TYPE_LEVEL_HIGH>;
				device_id = <0>;
				iommus = <&mmu_aw 4 1>;
			};
			isp1: isp@2102000 {
				compatible = "allwinner,sunxi-isp";
				reg = <0x0 0x02102000 0x0 0x2000>;
				interrupts = <GIC_SPI 78 IRQ_TYPE_LEVEL_HIGH>;
				device_id = <1>;
				iommus = <&mmu_aw 4 1>;
			};
			scaler0: scaler@2110000 {
				compatible = "allwinner,sunxi-scaler";
				reg = <0x0 0x02110000 0x0 0x400>;
				device_id = <0>;
				iommus = <&mmu_aw 3 1>;
			};
			scaler1: scaler@2110400 {
				compatible = "allwinner,sunxi-scaler";
				reg = <0x0 0x02110400 0x0 0x400>;
				device_id = <1>;
				iommus = <&mmu_aw 3 1>;
			};
			scaler2: scaler@2110800 {
				compatible = "allwinner,sunxi-scaler";
				reg = <0x0 0x02110800 0x0 0x400>;
				device_id = <2>;
				iommus = <&mmu_aw 3 1>;
			};
			scaler3: scaler@2110c00 {
				compatible = "allwinner,sunxi-scaler";
				reg = <0x0 0x02110C00 0x0 0x400>;
				device_id = <3>;
				iommus = <&mmu_aw 3 1>;
			};
			actuator0: actuator@2108180 {
				compatible = "allwinner,sunxi-actuator";
				device_type = "actuator0";
				reg = <0x0 0x02108180 0x0 0x10>;
				actuator0_name = "ad5820_act";
				actuator0_slave = <0x18>;
				actuator0_af_pwdn = <>;
				actuator0_afvdd = "afvcc-csi";
				actuator0_afvdd_vol = <2800000>;
				status = "disabled";
			};
			flash0: flash@2108190 {
				device_type = "flash0";
				compatible = "allwinner,sunxi-flash";
				reg = <0x0 0x02108190 0x0 0x10>;
				flash0_type = <2>;
				flash0_en = <>;
				flash0_mode = <>;
				flash0_flvdd = "";
				flash0_flvdd_vol = <>;
				device_id = <0>;
				status = "disabled";
			};
			sensor0: sensor@200b800 {
				reg = <0x0 0x0200B800 0x0 0x10>;
				device_type = "sensor0";
				compatible = "allwinner,sunxi-sensor";
				sensor0_mname = "ov5640";
				sensor0_twi_cci_id = <2>;
				sensor0_twi_addr = <0x78>;
				sensor0_mclk_id = <0>;
				sensor0_pos = "rear";
				sensor0_isp_used = <0>;
				sensor0_fmt = <0>;
				sensor0_stby_mode = <0>;
				sensor0_vflip = <0>;
				sensor0_hflip = <0>;
				sensor0_iovdd-supply = <>;
				sensor0_iovdd_vol = <>;
				sensor0_avdd-supply = <>;
				sensor0_avdd_vol = <>;
				sensor0_dvdd-supply = <>;
				sensor0_dvdd_vol = <>;
				sensor0_power_en = <>;
				sensor0_reset = <&pio PE 9 GPIO_ACTIVE_LOW>;
				sensor0_pwdn = <&pio PE 8 GPIO_ACTIVE_LOW>;
				sensor0_sm_vs = <>;
				flash_handle = <&flash0>;
				act_handle = <&actuator0>;
				device_id = <0>;
			};
			sensor1: sensor@200b810 {
				reg = <0x0 0x0200B810 0x0 0x10>;
				device_type = "sensor1";
				compatible = "allwinner,sunxi-sensor";
				sensor1_mname = "ov5647";
				sensor1_twi_cci_id = <3>;
				sensor1_twi_addr = <0x6c>;
				sensor1_mclk_id = <1>;
				sensor1_pos = "front";
				sensor1_isp_used = <0>;
				sensor1_fmt = <0>;
				sensor1_stby_mode = <0>;
				sensor1_vflip = <0>;
				sensor1_hflip = <0>;
				sensor1_iovdd-supply = <>;
				sensor1_iovdd_vol = <>;
				sensor1_avdd-supply = <>;
				sensor1_avdd_vol = <>;
				sensor1_dvdd-supply = <>;
				sensor1_dvdd_vol = <>;
				sensor1_power_en = <>;
				sensor1_reset = <&pio PE 7 GPIO_ACTIVE_LOW>;
				sensor1_pwdn = <&pio PE 6 GPIO_ACTIVE_LOW>;
				sensor1_sm_vs = <>;
				flash_handle = <>;
				act_handle = <>;
				device_id = <1>;
			};
			vinc0: vinc@2009000 {
				compatible = "allwinner,sunxi-vin-core";
				device_type = "vinc0";
				reg = <0x0 0x02009000 0x0 0x200>;
				interrupts = <GIC_SPI 71 IRQ_TYPE_LEVEL_HIGH>;
				vinc0_csi_sel = <1>;
				vinc0_mipi_sel = <0xff>;
				vinc0_isp_sel = <1>;
				vinc0_tdm_rx_sel = <0xff>;
				vinc0_rear_sensor_sel = <0>;
				vinc0_front_sensor_sel = <0>;
				vinc0_sensor_list = <0>;
				device_id = <0>;
				iommus = <&mmu_aw 3 1>;
			};
			vinc1: vinc@2009200 {
				device_type = "vinc1";
				compatible = "allwinner,sunxi-vin-core";
				reg = <0x0 0x02009200 0x0 0x200>;
				interrupts = <GIC_SPI 72 IRQ_TYPE_LEVEL_HIGH>;
				vinc1_csi_sel = <1>;
				vinc1_mipi_sel = <0xff>;
				vinc1_isp_sel = <1>;
				vinc1_tdm_rx_sel = <0xff>;
				vinc1_rear_sensor_sel = <0>;
				vinc1_front_sensor_sel = <0>;
				vinc1_sensor_list = <0>;
				device_id = <1>;
				iommus = <&mmu_aw 3 1>;
			};
			vinc2: vinc@2009400 {
				device_type = "vinc2";
				compatible = "allwinner,sunxi-vin-core";
				reg = <0x0 0x02009400 0x0 0x200>;
				interrupts = <GIC_SPI 73 IRQ_TYPE_LEVEL_HIGH>;
				vinc2_csi_sel = <0>;
				vinc2_mipi_sel = <0xff>;
				vinc2_isp_sel = <1>;
				vinc2_tdm_rx_sel = <0xff>;
				vinc2_rear_sensor_sel = <0>;
				vinc2_front_sensor_sel = <1>;
				vinc2_sensor_list = <0>;
				device_id = <2>;
				iommus = <&mmu_aw 3 1>;
			};
			vinc3: vinc@2009600 {
				device_type = "vinc3";
				compatible = "allwinner,sunxi-vin-core";
				reg = <0x0 0x02009600 0x0 0x200>;
				interrupts = <GIC_SPI 74 IRQ_TYPE_LEVEL_HIGH>;
				vinc3_csi_sel = <0>;
				vinc3_mipi_sel = <0xff>;
				vinc3_isp_sel = <1>;
				vinc3_tdm_rx_sel = <0xff>;
				vinc3_rear_sensor_sel = <0>;
				vinc3_front_sensor_sel = <1>;
				vinc3_sensor_list = <0>;
				device_id = <3>;
				iommus = <&mmu_aw 3 1>;
			};
		};

		keyboard: keyboard@5070800 {
			compatible = "allwinner,keyboard_1350mv";
			reg = <0x0 0x05070800 0x0 0x400>;
			interrupts = <GIC_SPI 22 IRQ_TYPE_EDGE_RISING>;
			clocks = <&ccu CLK_BUS_LRADC>;
			resets = <&ccu RST_BUS_LRADC>;
			key_cnt = <5>;
			key0 = <210 115>;
			key1 = <410 114>;
			key2 = <590 139>;
			key3 = <750 28>;
			key4 = <880 102>;
		};

		spi0: spi@5010000 {
			#address-cells = <1>;
			#size-cells = <0>;
			compatible = "allwinner,sun50i-spi";
			device_type = "spi0";
			reg = <0x0 0x05010000 0x0 0x1000>;
			interrupts = <GIC_SPI 13 IRQ_TYPE_LEVEL_HIGH>;
			clocks = <&ccu CLK_PLL_PERIPH0>, <&ccu CLK_SPI0>, <&ccu CLK_BUS_SPI0>;
			clock-names = "pll", "mod", "bus";
			resets = <&ccu RST_BUS_SPI0>;
			clock-frequency = <100000000>;
			pinctrl-names = "default", "sleep";
			pinctrl-0 = <&spi0_pins_a &spi0_pins_b>;
			pinctrl-1 = <&spi0_pins_c>;
			spi0_cs_number = <1>;
			spi0_cs_bitmap = <1>;
			dmas = <&dma 22>, <&dma 22>;
			dma-names = "tx", "rx";
			status = "disabled";
		};

		spi1: spi@5011000 {
			#address-cells = <1>;
			#size-cells = <0>;
			compatible = "allwinner,sun50i-spi";
			device_type = "spi1";
			reg = <0x0 0x05011000 0x0 0x1000>;
			interrupts = <GIC_SPI 14 IRQ_TYPE_LEVEL_HIGH>;
			clocks = <&ccu CLK_PLL_PERIPH0>, <&ccu CLK_SPI1>, <&ccu CLK_BUS_SPI1>;
			clock-names = "pll", "mod", "bus";
			resets = <&ccu RST_BUS_SPI1>;
			clock-frequency = <100000000>;
			pinctrl-names = "default", "sleep";
			pinctrl-0 = <&spi1_pins_a &spi1_pins_b>;
			pinctrl-1 = <&spi1_pins_c>;
			spi1_cs_number = <1>;
			spi1_cs_bitmap = <1>;
			dmas = <&dma 23>, <&dma 23>;
			dma-names = "tx", "rx";
			status = "disabled";
		};

		spi2: spi@5012000 {
			#address-cells = <1>;
			#size-cells = <0>;
			compatible = "allwinner,sun50i-spi";
			device_type = "spi2";
			reg = <0x0 0x05012000 0x0 0x1000>;
			interrupts = <GIC_SPI 15 IRQ_TYPE_LEVEL_HIGH>;
			clocks = <&ccu CLK_PLL_PERIPH0>, <&ccu CLK_SPI2>, <&ccu CLK_BUS_SPI2>;
			clock-names = "pll", "mod", "bus";
			resets = <&ccu RST_BUS_SPI2>;
			clock-frequency = <100000000>;
			pinctrl-names = "default", "sleep";
			pinctrl-0 = <&spi2_pins_a &spi2_pins_b>;
			pinctrl-1 = <&spi2_pins_c>;
			spi2_cs_number = <1>;
			spi2_cs_bitmap = <1>;
			dmas = <&dma 24>, <&dma 24>;
			dma-names = "tx", "rx";
			status = "disabled";
		};

		ledc: ledc@0x5018000 {
			#address-cells = <1>;
			#size-cells = <0>;
			compatible = "allwinner,sunxi-leds";
			reg = <0x0 0x05018000 0x0 0x100>;
			interrupts = <GIC_SPI 35 IRQ_TYPE_LEVEL_HIGH>;
			interrupt-names = "ledcirq";
			clocks = <&ccu CLK_LEDC>, <&ccu CLK_BUS_LEDC>;
			clock-names = "clk_ledc", "clk_cpuapb";
			pinctrl-0 = <&ledc_pins_a>;
			pinctrl-1 = <&ledc_pins_b>;
			pinctrl-names = "default", "sleep";
			dmas = <&dma 0>, <&dma 11>;
			dma-names = "rx", "tx";
			resets = <&ccu RST_BUS_LEDC>;
			reset-names = "ledc_reset";
			status = "disable";
		};

		usbc0: usbc0@10 {
			device_type = "usbc0";
			compatible = "allwinner,sunxi-otg-manager";
			reg = <0x0 0x10 0x0 0x1000>;
			usb_port_type = <2>;
			usb_detect_type = <1>;
			usb_id_gpio;
			usb_det_vbus_gpio;
			usb_wakeup_suspend = <0>;
			usb_serial_unique = <0>;
			usb_serial_number = "20080411";
			rndis_wceis = <1>;
		};

		udc: udc-controller@5100000 {
			compatible = "allwinner,sunxi-udc";
			reg = <0x0 0x05100000 0x0 0x1000>, /*udc base*/
			      <0x0 0x00000000 0x0 0x100>, /*sram base*/
			      <0x0 0x05200000 0x0 0x1000>; /*usb1 base, for common circuit*/
			interrupts = <GIC_SPI 32 IRQ_TYPE_LEVEL_HIGH>;
			clocks = <&ccu CLK_BUS_OTG>, <&ccu CLK_USB_PHY0>;
			clock-names = "bus_otg", "phy";
			resets = <&ccu RST_BUS_OTG>, <&ccu RST_USB_PHY0>;
			reset-names = "otg", "phy";
		};

		ehci0: ehci0-controller@5101000 {
			compatible = "allwinner,sunxi-ehci0";
			reg = <0x0 0x05101000 0x0 0xFFF>, /*ehci0 base*/
			      <0x0 0x00000000 0x0 0x100>, /*sram base*/
			      <0x0 0x05100000 0x0 0x1000>, /*otg base*/
			      <0x0 0x07010250 0x0 0x10>,   /*prcm base, for usb standby*/
			      <0x0 0x03001000 0x0 0x20>,   /*ccmu base, for common circuit*/
			      <0x0 0x05200000 0x0 0x1000>; /*usb1 base, for common circuit*/
			interrupts = <GIC_SPI 30 IRQ_TYPE_LEVEL_HIGH>;
			clocks = <&ccu CLK_BUS_EHCI0>, <&ccu CLK_USB_PHY0>;
			clock-names = "bus_hci", "phy";
			resets = <&ccu RST_BUS_EHCI0>, <&ccu RST_USB_PHY0>;
			reset-names = "hci", "phy";
			hci_ctrl_no = <0>;
		};

		ohci0: ohci0-controller@5101400 {
			compatible = "allwinner,sunxi-ohci0";
			reg = <0x0 0x05101400 0x0 0xFFF>, /*ohci0 base*/
			      <0x0 0x00000000 0x0 0x100>, /*sram base*/
			      <0x0 0x05100000 0x0 0x1000>, /*otg base*/
			      <0x0 0x07010250 0x0 0x10>,   /*prcm base, for usb standby*/
			      <0x0 0x03001000 0x0 0x20>,   /*ccmu base, for common circuit*/
			      <0x0 0x05200000 0x0 0x1000>; /*usb1 base, for common circuit*/
			interrupts = <GIC_SPI 31 IRQ_TYPE_LEVEL_HIGH>;
			clocks = <&ccu CLK_BUS_OHCI0>, <&ccu CLK_USB_OHCI0>, <&ccu CLK_USB_PHY0>;
			clock-names = "bus_hci", "ohci", "phy";
			resets = <&ccu RST_BUS_OHCI0>, <&ccu RST_USB_PHY0>;
			reset-names = "hci", "phy";
			hci_ctrl_no = <0>;
		};

		usbc1: usbc1@11 {
			device_type = "usbc1";
			reg = <0x0 0x11 0x0 0x1000>;
			usb_wakeup_suspend = <0>;
		};

		ehci1: ehci1-controller@5200000 {
			compatible = "allwinner,sunxi-ehci1";
			reg = <0x0 0x05200000 0x0 0xFFF>, /*ehci0 base*/
			      <0x0 0x00000000 0x0 0x100>, /*sram base*/
			      <0x0 0x05100000 0x0 0x1000>, /*otg base*/
			      <0x0 0x07010250 0x0 0x10>;   /*prcm base, for usb standby*/
			interrupts = <GIC_SPI 33 IRQ_TYPE_LEVEL_HIGH>;
			clocks = <&ccu CLK_BUS_EHCI1>, <&ccu CLK_USB_PHY1>;
			clock-names = "bus_hci", "phy";
			resets = <&ccu RST_BUS_EHCI1>, <&ccu RST_USB_PHY1>;
			reset-names = "hci", "phy";
			hci_ctrl_no = <1>;
		};

		ohci1: ohci1-controller@5200400 {
			compatible = "allwinner,sunxi-ohci1";
			reg = <0x0 0x05200400 0x0 0xFFF>, /*ohci0 base*/
			      <0x0 0x00000000 0x0 0x100>, /*sram base*/
			      <0x0 0x05100000 0x0 0x1000>, /*otg base*/
			      <0x0 0x07010250 0x0 0x10>;   /*prcm base, for usb standby*/
			interrupts = <GIC_SPI 34 IRQ_TYPE_LEVEL_HIGH>;
			clocks = <&ccu CLK_BUS_OHCI1>, <&ccu CLK_USB_OHCI1>, <&ccu CLK_USB_PHY1>;
			clock-names = "bus_hci", "ohci", "phy";
			resets = <&ccu RST_BUS_OHCI1>, <&ccu RST_USB_PHY1>;
			reset-names = "hci", "phy";
			hci_ctrl_no = <1>;
		};

		disp1: disp1@1 {
			compatible = "allwinner,sunxi-disp";
		};

		disp: disp@6000000 {
			compatible = "allwinner,sunxi-disp";
			reg = <0x0 0x06000000 0x0 0x3fffff>,	/* de0 */
			      <0x0 0x06800000 0x0 0x3fffff>,	/* de1 */
			      <0x0 0x06510000 0x0 0xfff>,	/* tcon-top0 */
			      <0x0 0x06d10000 0x0 0xfff>,	/* tcon-top1 */
			      <0x0 0x06511000 0x0 0xfff>,	/* tcon-lcd0 */
			      <0x0 0x06d11000 0x0 0xfff>,	/* tcon-lcd1 */
			      <0x0 0x06504000 0x0 0x1fff>;	/* dsi0*/
			interrupts = <GIC_SPI 69 IRQ_TYPE_LEVEL_HIGH>,
				     <GIC_SPI 70 IRQ_TYPE_LEVEL_HIGH>,
				     <GIC_SPI 68 IRQ_TYPE_LEVEL_HIGH>;
			clocks = <&ccu CLK_DE0>,
				 <&ccu CLK_DE1>,
				 <&ccu CLK_BUS_DE0>,
				 <&ccu CLK_BUS_DE1>,
				 <&ccu CLK_BUS_DPSS_TOP0>,
				 <&ccu CLK_BUS_DPSS_TOP1>,
				 <&ccu CLK_MIPI_DSI>,
				 <&ccu CLK_BUS_MIPI_DSI>,
				 <&ccu CLK_TCON_LCD0>,
				 <&ccu CLK_TCON_LCD1>,
				 <&ccu CLK_BUS_TCON_LCD0>,
				 <&ccu CLK_BUS_TCON_LCD1>,
				 <&ccu CLK_PLL_COM>;
			clock-names = "clk_de0",
					"clk_de1",
					"clk_bus_de0",
					"clk_bus_de1",
					"clk_bus_dpss_top0",
					"clk_bus_dpss_top1",
					"clk_mipi_dsi0",
					"clk_bus_mipi_dsi0",
					"clk_tcon0",
					"clk_tcon1",
					"clk_bus_tcon0",
					"clk_bus_tcon1",
					"clk_pll_com";
			resets = <&ccu RST_BUS_DE0>,
				 <&ccu RST_BUS_DE1>,
				 <&ccu RST_BUS_DPSS_TOP0>,
				 <&ccu RST_BUS_DPSS_TOP1>,
				 <&ccu RST_BUS_MIPI_DSI>,
				 <&ccu RST_BUS_TCON_LCD0>,
				 <&ccu RST_BUS_TCON_LCD1>,
				 <&ccu RST_BUS_LVDS0>,
				 <&ccu RST_BUS_LVDS1>;
			reset-names = "rst_bus_de0",
					"rst_bus_de1",
					"rst_bus_dpss_top0",
					"rst_bus_dpss_top1",
					"rst_bus_mipi_dsi0",
					"rst_bus_tcon0",
					"rst_bus_tcon1",
					"rst_bus_lvds0",
					"rst_bus_lvds1";

			assigned-clocks = <&ccu CLK_DE0>,
			<&ccu CLK_DE1>,
			<&ccu CLK_MIPI_DSI>,
			<&ccu CLK_TCON_LCD0>,
			<&ccu CLK_TCON_LCD1>;
			assigned-clock-parents = <&ccu CLK_PLL_PERIPH0_2X>,
			<&ccu CLK_PLL_PERIPH0_2X>,
			<&ccu CLK_PLL_PERIPH0>,
			<&ccu CLK_PLL_VIDEO0_4X>,
			<&ccu CLK_PLL_VIDEO1_4X>;
			assigned-clock-rates = <300000000>,
			<300000000>,
			<0>,
			<0>,
			<0>;

			boot_disp = <0>;
			boot_disp1 = <0>;
			boot_disp2 = <0>;
			fb_base = <0>;
			iommus = <&mmu_aw 0 0>;
		};

		lcd0_1: lcd0_1@1c0c000 {
			/*use for compatible panel*/
		};

		lcd0: lcd0@1c0c000 {
			compatible = "allwinner,sunxi-lcd0";
			reg = <0x0 0x1c0c000 0x0 0x0>;  /* Fake registers to avoid dtc compiling warnings */
			pinctrl-names = "active","sleep";
		};

		lcd1: lcd1@1 {
			compatible = "allwinner,sunxi-lcd1";
			reg = <0x0 0x1c0c000 0x0 0x0>;  /* Fake registers to avoid dtc compiling warnings */
			pinctrl-names = "active","sleep";
		};
		eink: eink@6400000 {
			compatible = "allwinner,sunxi-eink";
			pinctrl-names = "active","sleep";
			reg = <0x0 0x06400000 0x0 0x01ffff>,/* eink */
			      <0x0 0x06000000 0x0 0x3fffff>;/* de */
			interrupts = <GIC_SPI 90 IRQ_TYPE_LEVEL_HIGH>, /* eink */
				     <GIC_SPI 88 IRQ_TYPE_LEVEL_HIGH>; /* de */
			clocks = <&ccu CLK_DE0>,
			       <&ccu CLK_BUS_DE0>,
			       <&ccu CLK_BUS_EINK>,
			       <&ccu CLK_EINK>,
			       <&ccu CLK_EINK_PANEL>;
			clock-names = "de0",
				       "bus_de0",
				       "bus_eink",
				       "eink",
				       "eink_panel";
			resets = <&ccu RST_BUS_DE0>,
			       <&ccu RST_BUS_EINK>;
			reset-names = "rst_bus_de0",
				"rst_bus_eink";
			iommus = <&mmu_aw 6 1>;
			status = "okay";
		};

		tps65185: tps65185@68 {
			compatible = "allwinner,tps65185";
			pinctrl-names = "active","sleep";
			status = "okay";
		};

		tps65185_slave: tps65185_slave@68{
			compatible = "allwinner,tps65185_slave";
			pinctrl-names = "active","sleep";
			status = "okay";
		};


		ve: ve@1c0e000 {
			compatible = "allwinner,sunxi-cedar-ve";
			reg = <0x0 0x01c0e000 0x0 0x1000>,
			      <0x0 0x03000000 0x0 0x10>,
			      <0x0 0x03001000 0x0 0x1000>;
			interrupts = <GIC_SPI 94 IRQ_TYPE_LEVEL_HIGH>;
			clocks = <&ccu CLK_BUS_VE>, <&ccu CLK_VE>, <&ccu CLK_MBUS_VE>;
			clock-names = "bus_ve", "ve", "mbus_ve";
			resets = <&ccu RST_BUS_VE>;
			iommus = <&mmu_aw 2 1>;
		};

		g2d: g2d@6480000 {
			compatible = "allwinner,sunxi-g2d";
			reg = <0x0 0x06480000 0x0 0x3ffff>;
			interrupts = <GIC_SPI 91 IRQ_TYPE_LEVEL_HIGH>;
			clocks = <&ccu CLK_BUS_G2D>, <&ccu CLK_G2D>, <&ccu CLK_MBUS_G2D>;
			clock-names = "bus", "g2d", "mbus_g2d";
			resets = <&ccu RST_BUS_G2D>;
			iommus = <&mmu_aw 5 1>;
			assigned-clocks = <&ccu CLK_G2D>;
			assigned-clock-rates = <300000000>;
		};

		gralloc: gralloc@0 {
			compatible = "allwinner,sunxi-gralloc";
			status = "ok";
		};

		pinctrl_test: pinctrl_test@0 {
			reg = <0x0 0x0 0x0 0x0>;
			compatible = "allwinner,sunxi-pinctrl-test";
			device_type = "pinctrl-test";
			/* For pin state selecting test */
			pinctrl-0 = <&test_pins_a>;
			pinctrl-1 = <&test_pins_b>;
			pinctrl-names = "default", "sleep";
			/* For pin basic_function/irq test */
			test-gpios = <&pio PB 2 GPIO_ACTIVE_LOW>;
			suspend-gpios = <&r_pio PL 4 GPIO_ACTIVE_LOW>;  /* PA 0 0=in/1=out drive pull level */
			wakeup-source;
			interrupt-parent = <&pio>;
			interrupts = <PB 3 IRQ_TYPE_LEVEL_HIGH>;
		};

		gpio_para:gpio_para {
			device_type = "gpio_para";
			compatible = "allwinner,sunxi-init-gpio";
			status = "disabled";
		};

		/* codec addr: 0x05096000, the others is invalid to avoid build warining */
		codec:codec@5096000 {
			#sound-dai-cells = <0>;
			compatible = "allwinner,sunxi-internal-codec";
			reg = <0x0 0x05096000 0x0 0x32c>;
			clocks = <&ccu CLK_PLL_AUDIO>,	/* 98.304M / 90.3168M */
				 <&ccu CLK_AUDIO_DAC>,
				 <&ccu CLK_AUDIO_ADC>,
				 <&ccu CLK_PLL_COM>,
				 <&ccu CLK_PLL_COM_AUDIO>,
				 <&ccu CLK_BUS_AUDIO_CODEC>;
			clock-names = "pll_audio", "codec_dac", "codec_adc",
				      "pll_com", "pll_com_audio", "codec_bus";
			resets = <&ccu RST_BUS_AUDIO_CODEC>;
			playback_cma	= <128>;
			capture_cma	= <256>;
			device_type = "codec";
		};

		dummy_cpudai:dummy_cpudai@509632c {
			compatible = "allwinner,sunxi-dummy-cpudai";
			reg = <0x0 0x0509632c 0x0 0x4>;
			tx_fifo_size	= <128>;
			rx_fifo_size	= <256>;
			dac_txdata	= <0x05096020>;
			adc_txdata	= <0x05096040>;
			playback_cma	= <128>;
			capture_cma	= <256>;
			device_type = "cpudai";
			dmas = <&dma 7>, <&dma 7>;
			dma-names = "tx", "rx";
		};

		sndcodec:sound@5096330 {
			compatible = "allwinner,sunxi-codec-machine";
			reg = <0x0 0x05096330 0x0 0x4>;
			interrupts = <GIC_SPI 25 IRQ_TYPE_LEVEL_HIGH>;
			hp_detect_case = <0x00>;
			sunxi,audio-codec = <&codec>;
			sunxi,cpudai-controller = <&dummy_cpudai>;
			device_type = "sndcodec";
		};

		/* spdif addr: 0x05094000, the others is invalid to avoid build warining */
		spdif:spdif@5094000{
			#sound-dai-cells = <0>;
			compatible = "allwinner,sunxi-spdif";
			reg = <0x0 0x05094000 0x0 0x40>;
			clocks = <&ccu CLK_PLL_AUDIO>,	/* 98.304M / 90.3168M */
				 <&ccu CLK_SPDIF>,
				 <&ccu CLK_BUS_SPDIF>;
			clock-names = "pll_audio", "spdif", "spdif_bus";
			resets = <&ccu RST_BUS_SPDIF>;
			pinctrl-names = "default","sleep";
			pinctrl-0 = <&spdif_pins_a>;
			pinctrl-1 = <&spdif_pins_b>;
			clk_parent	= <0x1>;
			playback_cma	= <128>;
			capture_cma	= <128>;
			device_type = "spdif";
			dmas = <&dma 2>, <&dma 2>;
			dma-names = "tx", "rx";
		};

		soundspdif:soundspdif@5094040 {
			reg = <0x0 0x05094040 0x0 0x4>;
			 compatible = "sunxi,simple-audio-card";
			 simple-audio-card,name = "sndspdif";
			 /* simple-audio-card,format = "i2s"; */
			 simple-audio-card,cpu {
				 sound-dai = <&spdif>;
			 };

			 simple-audio-card,codec {
				 /*snd-soc-dummy*/
			 };
		 };

		/* dmic addr: 0x05095000, the others is invalid to avoid build warining */
		dmic:dmic@5095000{
			#sound-dai-cells = <0>;
			compatible = "allwinner,sunxi-dmic";
			reg = <0x0 0x05095000 0x0 0x50>;
			clocks = <&ccu CLK_PLL_AUDIO>, /* 98.304M / 90.3168M */
				 <&ccu CLK_DMIC>,
				 <&ccu CLK_BUS_DMIC>;
			clock-names = "pll_audio", "dmic", "dmic_bus";
			resets = <&ccu RST_BUS_DMIC>;
			pinctrl-names = "default","sleep";
			pinctrl-0 = <&dmic_pins_a>;
			pinctrl-1 = <&dmic_pins_b>;
			clk_parent	= <0x1>;
			capture_cma	= <256>;
			data_vol	= <0xB0>;
			dmic_rxsync_en	= <0x0>;
			rx_chmap	= <0x76543210>;
			device_type = "dmic";
			dmas = <&dma 8>;
			dma-names = "rx";
		};

		dmic_codec:sound@5095050{
			#sound-dai-cells = <0>;
			compatible = "dmic-codec";
			reg = <0x0 0x05095050 0x0 0x4>;
			num-channels = <8>;
		};

		sounddmic:sounddmic@5095060 {
			reg = <0x0 0x05095060 0x0 0x4>;
			compatible = "sunxi,simple-audio-card";
			simple-audio-card,name = "snddmic";
			simple-audio-card,capture_only;
			/* simple-audio-card,format = "i2s"; */
			simple-audio-card,cpu {
				sound-dai = <&dmic>;
			};

			simple-audio-card,codec {
				sound-dai = <&dmic_codec>;
			};
		};

		/* daudio0 addr: 0x05090000, the others is invalid to avoid build warining */
		daudio0:daudio@5090000 {
			#sound-dai-cells = <0>;
			compatible = "allwinner,sunxi-daudio";
			reg = <0x0 0x05090000 0x0 0x7c>;
			clocks = <&ccu CLK_PLL_AUDIO>, /* 98.304M / 90.3168M */
				 <&ccu CLK_I2S0>,
				 <&ccu CLK_BUS_I2S0>;
			clock-names = "pll_audio", "i2s0", "i2s0_bus";
			resets = <&ccu RST_BUS_I2S0>;
			pinctrl-names = "default", "sleep";
			pinctrl-0 = <&daudio0_pins_a>;
			pinctrl-1 = <&daudio0_pins_b>;
			pinctrl_used		= <0x01>;
			sign_extend		= <0x00>;
			tx_data_mode		= <0x00>;
			rx_data_mode		= <0x00>;
			msb_lsb_first		= <0x00>;
			daudio_rxsync_en	= <0x00>;
			pcm_lrck_period		= <0x80>;
			slot_width_select	= <0x20>;
			frametype		= <0x00>;
			tdm_config		= <0x01>;
			tdm_num			= <0x00>;
			mclk_div		= <0x00>;
			clk_parent		= <0x01>;
			capture_cma		= <128>;
			playback_cma		= <128>;
			tx_num			= <4>;
			tx_chmap1		= <0x76543210>;
			tx_chmap0		= <0xFEDCBA98>;
			rx_num			= <4>;
			rx_chmap3		= <0x03020100>;
			rx_chmap2		= <0x07060504>;
			rx_chmap1		= <0x0B0A0908>;
			rx_chmap0		= <0x0F0E0D0C>;
			device_type = "daudio0";
			dmas = <&dma 3>, <&dma 3>;
			dma-names = "tx", "rx";
		};

		sounddaudio0: sounddaudio0@509007c {
			reg = <0x0 0x0509007c 0x0 0x4>;
			compatible = "sunxi,simple-audio-card";
			simple-audio-card,name = "snddaudio0";
			simple-audio-card,format = "i2s";
			/* simple-audio-card,frame-master = <&daudio0_master>; */
			/* simple-audio-card,bitclock-master = <&daudio0_master>; */
			/* simple-audio-card,bitclock-inversion; */
			/* simple-audio-card,frame-inversion; */
			simple-audio-card,cpu {
				sound-dai = <&daudio0>;
			};
			daudio0_master: simple-audio-card,codec {
				 /* sound-dai = <&ac108>; */
			};
		 };

		/* daudio1 addr: 0x05091000, the others is invalid to avoid build warining */
		daudio1:daudio@5091000 {
			#sound-dai-cells = <0>;
			compatible = "allwinner,sunxi-daudio";
			reg = <0x0 0x05091000 0x0 0x7c>;
			clocks = <&ccu CLK_PLL_AUDIO>, /* 98.304M / 90.3168M */
				 <&ccu CLK_I2S1>,
				 <&ccu CLK_BUS_I2S1>;
			clock-names = "pll_audio", "i2s1", "i2s1_bus";
			resets = <&ccu RST_BUS_I2S1>;
			pinctrl-names = "default", "sleep";
			pinctrl-0 = <&daudio1_pins_a>;
			pinctrl-1 = <&daudio1_pins_b>;
			pinctrl_used		= <0x1>;
			sign_extend		= <0x00>;
			tx_data_mode		= <0x00>;
			rx_data_mode		= <0x00>;
			msb_lsb_first		= <0x00>;
			daudio_rxsync_en	= <0x0>;
			pcm_lrck_period		= <0x80>;
			slot_width_select	= <0x20>;
			frametype		= <0x00>;
			tdm_config		= <0x01>;
			tdm_num			= <0x1>;
			mclk_div		= <0x0>;
			clk_parent		= <0x1>;
			capture_cma		= <128>;
			playback_cma		= <128>;
			tx_num			= <4>;
			tx_chmap1		= <0x76543210>;
			tx_chmap0		= <0xFEDCBA98>;
			rx_num			= <4>;
			rx_chmap3		= <0x03020100>;
			rx_chmap2		= <0x07060504>;
			rx_chmap1		= <0x0B0A0908>;
			rx_chmap0		= <0x0F0E0D0C>;
			device_type = "daudio1";
			dmas = <&dma 4>, <&dma 4>;
			dma-names = "tx", "rx";
			status = "disabled";
		};

		sounddaudio1: sounddaudio1@509107c {
			reg = <0x0 0x0509107c 0x0 0x4>;
			compatible = "sunxi,simple-audio-card";
			simple-audio-card,name = "snddaudio1";
			simple-audio-card,format = "i2s";
			status = "disabled";
			simple-audio-card,cpu {
				sound-dai = <&daudio1>;
			};
			daudio1_master: simple-audio-card,codec {
				 /* snd-soc-dummy */
			};
		 };

		/* daudio2 addr: 0x05092000, the others is invalid to avoid build warining */
		daudio2:daudio@5092000 {
			#sound-dai-cells = <0>;
			compatible = "allwinner,sunxi-daudio";
			reg = <0x0 0x05092000 0x0 0x7c>;
			clocks = <&ccu CLK_PLL_AUDIO>, /* 98.304M / 90.3168M */
				 <&ccu CLK_I2S2>,
				 <&ccu CLK_BUS_I2S2>;
			clock-names = "pll_audio", "i2s2", "i2s2_bus";
			resets = <&ccu RST_BUS_I2S2>;
			pinctrl-names = "default", "sleep";
			pinctrl-0 = <&daudio2_pins_a>;
			pinctrl-1 = <&daudio2_pins_b>;
			pinctrl_used		= <0x1>;
			sign_extend		= <0x00>;
			tx_data_mode		= <0x00>;
			rx_data_mode		= <0x00>;
			msb_lsb_first		= <0x00>;
			daudio_rxsync_en	= <0x0>;
			pcm_lrck_period		= <0x80>;
			slot_width_select	= <0x20>;
			frametype		= <0x00>;
			tdm_config		= <0x01>;
			tdm_num			= <0x2>;
			mclk_div		= <0x0>;
			clk_parent		= <0x1>;
			capture_cma		= <128>;
			playback_cma		= <128>;
			tx_num			= <4>;
			tx_chmap1		= <0x76543210>;
			tx_chmap0		= <0xFEDCBA98>;
			rx_num			= <4>;
			rx_chmap3		= <0x03020100>;
			rx_chmap2		= <0x07060504>;
			rx_chmap1		= <0x0B0A0908>;
			rx_chmap0		= <0x0F0E0D0C>;
			device_type = "daudio2";
			dmas = <&dma 5>, <&dma 5>;
			dma-names = "tx", "rx";
			status = "disabled";
		};

		sounddaudio2: sounddaudio2@509207c {
			reg = <0x0 0x0509207c 0x0 0x4>;
			compatible = "sunxi,simple-audio-card";
			simple-audio-card,name = "snddaudio2";
			simple-audio-card,format = "i2s";
			status = "disabled";
			simple-audio-card,cpu {
				sound-dai = <&daudio2>;
			};
			daudio2_master: simple-audio-card,codec {
				 /* snd-soc-dummy */
			};
		 };

		/* daudio3 addr: 0x05093000, the others is invalid to avoid build warining */
		daudio3:daudio@5093000 {
			#sound-dai-cells = <0>;
			compatible = "allwinner,sunxi-daudio";
			reg = <0x0 0x05093000 0x0 0x7c>;
			clocks = <&ccu CLK_PLL_AUDIO>, /* 98.304M / 90.3168M */
				 <&ccu CLK_I2S3>,
				 <&ccu CLK_BUS_I2S3>;
			clock-names = "pll_audio", "i2s3", "i2s3_bus";
			resets = <&ccu RST_BUS_I2S3>;
			pinctrl-names = "default", "sleep";
			pinctrl-0 = <&daudio3_pins_a>;
			pinctrl-1 = <&daudio3_pins_b>;
			pinctrl_used		= <0x1>;
			sign_extend		= <0x00>;
			tx_data_mode		= <0x00>;
			rx_data_mode		= <0x00>;
			msb_lsb_first		= <0x00>;
			daudio_rxsync_en	= <0x0>;
			pcm_lrck_period		= <0x80>;
			slot_width_select	= <0x20>;
			frametype		= <0x00>;
			tdm_config		= <0x01>;
			tdm_num			= <0x3>;
			mclk_div		= <0x0>;
			clk_parent		= <0x1>;
			capture_cma		= <128>;
			playback_cma		= <128>;
			tx_num			= <4>;
			tx_chmap1		= <0x76543210>;
			tx_chmap0		= <0xFEDCBA98>;
			rx_num			= <4>;
			rx_chmap3		= <0x03020100>;
			rx_chmap2		= <0x07060504>;
			rx_chmap1		= <0x0B0A0908>;
			rx_chmap0		= <0x0F0E0D0C>;
			device_type = "daudio3";
			dmas = <&dma 6>, <&dma 6>;
			dma-names = "tx", "rx";
			status = "disabled";
		};

		sounddaudio3: sounddaudio3@509307c {
			reg = <0x0 0x0509307c 0x0 0x4>;
			compatible = "sunxi,simple-audio-card";
			simple-audio-card,name = "snddaudio3";
			simple-audio-card,format = "i2s";
			status = "disabled";
			simple-audio-card,cpu {
				sound-dai = <&daudio3>;
			};
			daudio3_master: simple-audio-card,codec {
				 /* snd-soc-dummy */
			};
		};

		r_pio: pinctrl@7022000 {
			compatible = "allwinner,sun50iw10p1-r-pinctrl";
			reg = <0x0 0x07022000 0x0 0x400>;
			interrupts = <GIC_SPI 111 IRQ_TYPE_LEVEL_HIGH>;
			clocks = <&r_ccu CLK_R_APB1>, <&dcxo24M>, <&rtc_ccu CLK_OSC32K>;
			clock-names = "apb", "hosc", "losc";
			device_type = "r_pio";
			gpio-controller;
			interrupt-controller;
			#interrupt-cells = <3>;
			#size-cells = <0>;
			#gpio-cells = <3>;

			s_rsb0_pins_a: s_rsb0@0 {
				pins = "PL0", "PL1";
				function = "s_rsb0";
				drive-strength = <20>;
				bias-pull-up;
			};

			s_uart0_pins_a: s_uart0@0 {
				pins = "PL2", "PL3";
				function = "s_uart0";
				drive-strength = <10>;
				bias-pull-up;
			};

			s_uart0_pins_b: s_uart0@1 {
				pins = "PL2", "PL3";
				function = "gpio_in";
			};

			s_twi0_pins_a: s_twi0@0 {
				pins = "PL0", "PL1";
				function = "s_twi0";
				drive-strength = <10>;
				bias-pull-up;
			};

			s_twi0_pins_b: s_twi0@1 {
				pins = "PL0", "PL1";
				function = "gpio_in";
			};

			s_twi1_pins_a: s_twi1@0 {
				pins = "PL8", "PL9";
				function = "s_twi1";
				drive-strength = <10>;
				bias-pull-up;
			};

			s_twi1_pins_b: s_twi1@1 {
				pins = "PL8", "PL9";
				function = "gpio_in";
			};

			s_cir0_pins_a: s_cir0@0{
				pins = "PL11";
				function = "s_cir0";
				drive-strength = <10>;
				bias-pull-up;
			};
		};

		pio: pinctrl@300b000 {
			compatible = "allwinner,sun50iw10p1-pinctrl";
			reg = <0x0 0x0300b000 0x0 0x400>;
			interrupts = <GIC_SPI 54 IRQ_TYPE_LEVEL_HIGH>,  /* AW1855_GIC_Spec: GPIOB: 86-32=54 */
				   <GIC_SPI 55 IRQ_TYPE_LEVEL_HIGH>,
				   <GIC_SPI 56 IRQ_TYPE_LEVEL_HIGH>,
				   <GIC_SPI 57 IRQ_TYPE_LEVEL_HIGH>,
				   <GIC_SPI 58 IRQ_TYPE_LEVEL_HIGH>,
				   <GIC_SPI 59 IRQ_TYPE_LEVEL_HIGH>,
				   <GIC_SPI 60 IRQ_TYPE_LEVEL_HIGH>,
				   <GIC_SPI 61 IRQ_TYPE_LEVEL_HIGH>,
				   <GIC_SPI 62 IRQ_TYPE_LEVEL_HIGH>;
			device_type = "pio";
			clocks = <&ccu CLK_APB1>, <&rtc_ccu CLK_OSC32K>, <&dcxo24M>;
			clock-names = "apb", "losc", "hosc";
			gpio-controller;
			interrupt-controller;
			#interrupt-cells = <3>;
			#size-cells = <0>;
			#gpio-cells = <3>;
			vcc-pf-supply = <&reg_pio1_8>;
			vcc-pfo-supply = <&reg_pio3_3>;
			input-debounce = <0 0 0 0 1 0 0 0 0>;

			test_pins_a: test_pins@0 {
				pins = "PB0", "PB1";
				function = "test";
				drive-strength = <10>;
				bias-pull-up;
			};
			test_pins_b: test_pins@1 {
				pins = "PB0", "PB1";
				function = "gpio_in";
			};

			/* FPGA stage: PB8 PB9, IC stage: PB9 PB10*/
			uart0_pins_a: uart0@0 {
				pins = "PB9", "PB10";
				function = "uart0";
				drive-strength = <10>;
				bias-pull-up;
			};

			uart0_pins_b: uart0@1 {
				pins = "PB9", "PB10";
				function = "uart0";
				drive-strength = <10>;
			};

			uart1_pins_a: uart1@0 {
				pins = "PG6", "PG7", "PG8", "PG9";
				function = "uart1";
				drive-strength = <10>;
				bias-pull-up;
			};

			uart1_pins_b: uart1@1 {
				pins = "PG6", "PG7", "PG8", "PG9";
				function = "gpio_in";
			};

			uart2_pins_a: uart2@0 {
				pins = "PB0", "PB1", "PB2", "PB3";
				function = "uart2";
				drive-strength = <10>;
				bias-pull-up;
			};

			uart2_pins_b: uart2@1 {
				pins = "PB0", "PB1", "PB2", "PB3";
				function = "gpio_in";
			};

			uart3_pins_a: uart3@0 {
				pins = "PH4", "PH5", "PH6", "PH7";
				function = "uart3";
				drive-strength = <10>;
				bias-pull-up;
			};

			uart3_pins_b: uart3@1 {
				pins = "PH4", "PH5", "PH6", "PH7";
				function = "gpio_in";
			};

			uart4_pins_a: uart4@0 {
				pins = "PD18", "PD19", "PD20", "PD21";
				function = "uart4";
				drive-strength = <10>;
				bias-pull-up;
			};

			uart4_pins_b: uart4@1 {
				pins = "PD18", "PD19", "PD20", "PD21";
				function = "gpio_in";
			};

			uart5_pins_a: uart5@0 {
				pins = "PI2", "PI3", "PI4", "PI5";
				function = "uart5";
				drive-strength = <10>;
				bias-pull-up;
			};

			uart5_pins_b: uart5@1 {
				pins = "PI2", "PI3", "PI4", "PI5";
				function = "gpio_in";
			};

			uart6_pins_a: uart6@0 {
				pins = "PI6", "PI7", "PI13", "PI14";
				function = "uart6";
				drive-strength = <10>;
				bias-pull-up;
			};

			uart6_pins_b: uart6@1 {
				pins = "PI6", "PI7", "PI13", "PI14";
				function = "gpio_in";
			};

			ir0_pins_a: ir0@0 {
				pins = "PH3";
				function = "ir0";
				drive-strength = <10>;
			};

			ir0_pins_b: ir0@1 {
				pins = "PH3";
				function = "gpio_in";
			};

			twi0_pins_a: twi0@0 {
				pins = "PH0", "PH1";
				function = "twi0";
				drive-strength = <10>;
			};

			twi0_pins_b: twi0@1 {
				pins = "PH0", "PH1";
				function = "gpio_in";
			};

			twi1_pins_a: twi1@0 {
				pins = "PH2", "PH3";
				function = "twi1";
				drive-strength = <10>;
			};

			twi1_pins_b: twi1@1 {
				pins = "PH2", "PH3";
				function = "gpio_in";
			};

			twi2_pins_a: twi2@0 {
				pins = "PE1", "PE2";
				function = "twi2";
				drive-strength = <10>;
			};

			twi2_pins_b: twi2@1 {
				pins = "PE1", "PE2";
				function = "gpio_in";
			};

			twi3_pins_a: twi3@0 {
				pins = "PE3", "PE4";
				function = "twi3";
				drive-strength = <10>;
			};

			twi3_pins_b: twi3@1 {
				pins = "PE3", "PE4";
				function = "gpio_in";
			};

			twi4_pins_a: twi4@0 {
				pins = "PI0", "PI1";
				function = "twi4";
				drive-strength = <10>;
			};

			twi4_pins_b: twi4@1 {
				pins = "PI0", "PI1";
				function = "gpio_in";
			};

			twi5_pins_a: twi5@0 {
				pins = "PI8", "PI9";
				function = "twi5";
				drive-strength = <10>;
			};

			twi5_pins_b: twi5@1 {
				pins = "PI8", "PI9";
				function = "gpio_in";
			};

			ts0_pins_a: ts0@0 {
				pins = "PD0", "PD1", "PD2", "PD3",
						 "PD4", "PD5", "PD6", "PD7",
						 "PD8", "PD9", "PD10", "PD11";
				function = "ts0";
				drive-strength = <10>;
			};

			ts0_pins_b: ts0_sleep@0 {
				pins = "PD0", "PD1", "PD2", "PD3",
						 "PD4", "PD5", "PD6", "PD7",
						 "PD8", "PD9", "PD10", "PD11";
				function = "gpio_in";
			};

			spi0_pins_a: spi0@0 {
				pins = "PC2", "PC4", "PC12", "PC15", "PC16";
				function = "spi0";
				drive-strength = <10>;
			};

			spi0_pins_b: spi0@1 {
				pins = "PC3", "PC7";
				function = "spi0";
				drive-strength = <10>;
				bias-pull-up;	/* only CS should be pulled up */
			};

			spi0_pins_c: spi0@2 {
				pins = "PC2", "PC3", "PC4", "PC7", "PC12", "PC15", "PC16";
				function = "gpio_in";
			};

			spi1_pins_a: spi1@0 {
				pins = "PD11", "PD12", "PD13";
				function = "spi1";
				drive-strength = <10>;
			};

			spi1_pins_b: spi1@1 {
				pins = "PD10";
				function = "spi1";
				drive-strength = <10>;
				bias-pull-up;	/* only CS should be pulled up */
			};

			spi1_pins_c: spi1@2 {
				pins = "PD10", "PD11", "PD12", "PD13";
				function = "gpio_in";
			};

			spi2_pins_a: spi2@0 {
				pins = "PB1", "PB2", "PB3";
				function = "spi2";
				drive-strength = <10>;
			};

			spi2_pins_b: spi2@1 {
				pins = "PB0";
				function = "spi2";
				drive-strength = <10>;
				bias-pull-up;	/* only CS should be pulled up */
			};

			spi2_pins_c: spi2@2 {
				pins = "PB0", "PB1", "PB2", "PB3";
				function = "gpio_in";
			};

			sdc0_pins_a: sdc0@0 {
				pins = "PF0", "PF1", "PF2",
				       "PF3", "PF4", "PF5";
				function = "sdc0";
				drive-strength = <30>;
				bias-pull-up;
				power-source = <3300>;
			};

			sdc0_pins_b: sdc0@1 {
				pins = "PF0", "PF1", "PF2",
				       "PF3", "PF4", "PF5";
				function = "sdc0";
				drive-strength = <30>;
				bias-pull-up;
				power-source = <1800>;
			};

			sdc0_pins_c: sdc0@2 {
				pins = "PF0", "PF1", "PF2",
				       "PF3", "PF4", "PF5";
				function = "gpio_in";
			};

			/* TODO: add jtag pin */
			sdc0_pins_d: sdc0@3 {
				pins = "PF2", "PF4";
				function = "uart0";
				drive-strength = <10>;
				bias-pull-up;
			};

			sdc0_pins_e: sdc0@4 {
				pins = "PF0", "PF1", "PF3",
					"PF5";
				function = "jtag";
				drive-strength = <10>;
				bias-pull-up;
			};

			sdc1_pins_a: sdc1@0 {
				pins = "PG0", "PG1", "PG2",
				       "PG3", "PG4", "PG5";
				function = "sdc1";
				drive-strength = <30>;
				bias-pull-up;
			};

			sdc1_pins_b: sdc1@1 {
				pins = "PG0", "PG1", "PG2",
				       "PG3", "PG4", "PG5";
				function = "gpio_in";
			};

			sdc2_pins_a: sdc2@0 {
				pins = "PC1", "PC5", "PC6",
				       "PC8", "PC9", "PC10", "PC11",
				       "PC13", "PC14", "PC15", "PC16";
				function = "sdc2";
				drive-strength = <30>;
				bias-pull-up;
			};

			sdc2_pins_b: sdc2@1 {
				pins = "PC0", "PC1", "PC5", "PC6",
				       "PC8", "PC9", "PC10", "PC11",
				       "PC13", "PC14", "PC15", "PC16";
				function = "gpio_in";
			};

			sdc2_pins_c: sdc2@2 {
				pins = "PC0";
				function = "sdc2";
				drive-strength = <30>;
				bias-pull-down;
			};

			sdc3_pins_a: sdc3@0 {
				pins = "PI14", "PI13", "PI12",
						 "PI11", "PI10", "PI9";
				function = "sdc3";
				drive-strength = <20>;
				bias-pull-up;
			};

			sdc3_pins_b: sdc3@1 {
				pins = "PI14", "PI13", "PI12",
						 "PI11", "PI10", "PI9";
				function = "gpio_in";
			};

			daudio0_pins_a: daudio0@0 {
				pins = "PB4", "PB5", "PB6", "PB7", "PB8";
				function = "h_i2s0";
				drive-strength = <10>;
			};

			daudio0_pins_b: daudio0_sleep@0 {
				pins = "PB4", "PB5", "PB6", "PB7", "PB8";
				function = "gpio_in";
			};

			daudio1_pins_a: daudio1@0 {
				pins = "PG9", "PG10", "PG11", "PG12", "PG13";
				function = "h_i2s1";
				drive-strength = <10>;
			};

			daudio1_pins_b: daudio1_sleep@0 {
				pins = "PG9", "PG10", "PG11", "PG12", "PG13";
				function = "gpio_in";
			};

			daudio2_pins_a: daudio2@0 {
				pins = "PE5", "PE6", "PE7", "PE8", "PE9";
				function = "h_i2s2";
				drive-strength = <10>;
			};

			daudio2_pins_b: daudio2_sleep@0 {
				pins = "PE5", "PE6", "PE7", "PE8", "PE9";
				function = "gpio_in";
			};

			daudio3_pins_a: daudio3@0 {
				pins = "PH13", "PH14", "PH15", "PH16", "PH17", "PH18", "PH19";
				function = "h_i2s3";
				drive-strength = <10>;
			};

			daudio3_pins_b: daudio3_sleep@0 {
				pins = "PH13", "PH14", "PH15", "PH16", "PH17", "PH18", "PH19";
				function = "gpio_in";
			};

			spdif_pins_a: spdif@0 {
				pins = "PH6", "PH7";
				function = "spdif";
				drive-strength = <10>;
			};

			spdif_pins_b: spdif_sleep@0 {
				pins = "PH6", "PH7";
				function = "gpio_in";
			};

			dmic_pins_a: dmic@0 {
				pins = "PH8", "PH9", "PH10", "PH11", "PH12";
				function = "dmic";
				drive-strength = <10>;
			};

			dmic_pins_b: dmic_sleep@0 {
				pins = "PH8", "PH9", "PH10", "PH11", "PH12";
				function = "gpio_in";
			};

			csi_mclk0_pins_a: csi_mclk0@0 {
				pins = "PE0";
				function = "csi_mclk0";
				drive-strength = <20>;
			};
			csi_mclk0_pins_b: csi_mclk0@1 {
				pins = "PE0";
				function = "gpio_in";
			};
			csi_mclk1_pins_a: csi_mclk1@0 {
				pins = "PE5";
				function = "csi_mclk1";
				drive-strength = <20>;
			};
			csi_mclk1_pins_b: csi_mclk1@1 {
				pins = "PE5";
				function = "gpio_in";
			};

			scr0_pins_a: scr0@0 {
				pins = "PG13", "PG14", "PG10", "PG11", "PG12";
				function = "sim0";
				bias-pull-up;
			};

			scr0_pins_b: scr0@1 {
				pins = "PG8", "PG9";
				function = "sim0";
				bias-pull-up;
			};

			scr0_pins_c: scr0@2 {
				pins = "PG8", "PG9", "PG10", "PG11", "PG12", "PG13", "PG14";
				function = "gpio_in";
			};

			scr1_pins_a: scr1@0 {
				pins = "PH5", "PH6", "PH2",
						 "PH3", "PH4";
				function = "sim1";
				drive-strength = <10>;
				bias-pull-up;
			};

			scr1_pins_b: scr1@1 {
				pins = "PH0", "PH1";
				function = "sim1";
				drive-strength = <10>;
				bias-pull-up;
			};

			scr1_pins_c: scr1@2 {
				pins = "PH0", "PH1", "PH2",
						 "PH3", "PH4", "PH5",
						 "PH6";
				function = "gpio_in";
			};

			nand0_pins_a: nand0@0 {
				pins = "PC0", "PC1", "PC2", "PC5",
						 "PC8", "PC9", "PC10", "PC11",
						 "PC12", "PC13", "PC14", "PC15",
						 "PC16";
				function = "nand0";
				drive-strength = <30>;
			};

			nand0_pins_b: nand0@1 {
				pins = "PC4", "PC6", "PC3", "PC7";
				function = "nand0";
				drive-strength = <30>;
				bias-pull-up;/* only RB&CE should be pulled up */
			};

			nand0_pins_c: nand0@2 {
				pins = "PC0", "PC1", "PC2", "PC3",
						 "PC4", "PC5", "PC6", "PC7",
						 "PC8", "PC9", "PC10", "PC11",
						 "PC12", "PC13", "PC14", "PC15",
						 "PC16";
				function = "gpio_in";
			};

			ccir_clk_pin_a: ac200@2 {
				pins = "PB0";
				function = "ac200";
				drive-strength = <10>;
			};

			ccir_clk_pin_b: ac200@3 {
				pins = "PB0";
				function = "gpio_in";
			};

			gmac_pins_a: gmac@0 {
				pins = "PH0", "PH1", "PH2", "PH3",
						 "PH4", "PH5", "PH6", "PH7",
						 "PH9", "PH10", "PH13", "PH14",
						 "PH15", "PH16", "PH17", "PH18";
				function = "gmac0";
				drive-strength = <30>;
			};

			gmac_pins_b: gmac@1 {
				pins = "PH0", "PH1", "PH2", "PH3",
						 "PH4", "PH5", "PH6", "PH7",
						 "PH9", "PH10", "PH13", "PH14",
						 "PH15", "PH16", "PH17", "PH18";
				function = "gpio_in";
			};

			gmac1_pins_a: gmac1@0 {
				pins = "PJ0", "PJ1", "PJ2", "PJ3",
						 "PJ4", "PJ5", "PJ6", "PJ7",
						 "PJ8", "PJ9", "PJ10", "PJ11",
						 "PJ12", "PJ13", "PJ14", "PJ15";
				function = "gmac1";
				drive-strength = <30>;
			};

			gmac1_pins_b: gmac1@1 {
				pins = "PJ0", "PJ1", "PJ2", "PJ3",
						 "PJ4", "PJ5", "PJ6", "PJ7",
						 "PJ8", "PJ9", "PJ10", "PJ11",
						 "PJ12", "PJ13", "PJ14", "PJ15";
				function = "gpio_in";
			};

			ledc_pins_a: ledc@0 {
				pins = "PE5";
				function = "ledc";
				drive-strength = <10>;
				bias-pull-up;
			};

			ledc_pins_b: ledc@1 {
				pins = "PE5";
				function = "gpio_in";
			};

			lvds0_pins_a: lvds0@0 {
				pins = "PD0", "PD1", "PD2", "PD3", "PD4", "PD5", "PD8", "PD9", "PD6", "PD7";
				function = "lvds0";
				drive-strength = <30>;
			};

			lvds0_pins_b: lvds0@1 {
				pins = "PD0", "PD1", "PD2", "PD3", "PD4", "PD5", "PD8", "PD9", "PD6", "PD7";
				function = "gpio_in";
			};

			lvds1_pins_a: lvds1@0 {
				pins = "PD10", "PD11", "PD12", "PD13", "PD14", "PD15", "PD18", "PD19", "PD16", "PD17";
				function = "lvds1";
				drive-strength = <30>;
			};
			lvds1_pins_b: lvds1@1 {
				pins = "PD10", "PD11", "PD12", "PD13", "PD14", "PD15", "PD18", "PD19", "PD16", "PD17";
				function = "gpio_in";
			};

			lvds2_pins_a: lvds2@0 {
				pins = "PJ7", "PJ6", "PJ5", "PJ4", "PJ3", "PJ2", "PJ1", "PJ0", "PJ8", "PJ9";
				function = "lvds2";
				drive-strength = <30>;
			};
			lvds2_pins_b: lvds2@1 {
				pins = "PJ7", "PJ6", "PJ5", "PJ4", "PJ3", "PJ2", "PJ1", "PJ0", "PJ8", "PJ9";
				function = "gpio_in";
			};

			lvds3_pins_a: lvds3@0 {
				pins = "PJ10", "PJ11", "PJ12", "PJ13", "PJ14", "PJ15", "PJ16", "PJ17", "PJ18", "PJ19";
				function = "lvds3";
				drive-strength = <30>;
			};

			lvds3_pins_b: lvds3@1 {
				pins = "PJ10", "PJ11", "PJ12", "PJ13", "PJ14", "PJ15", "PJ16", "PJ17", "PJ18", "PJ19";
				function = "gpio_in";
			};

			lcd1_lvds2link_pins_a: lcd1_lvds2link@0 {
				pins = "PJ10", "PJ11", "PJ12", "PJ13", "PJ14", "PJ15", "PJ16", "PJ17", "PJ18", "PJ19", \
				"PJ7", "PJ6", "PJ5", "PJ4", "PJ3", "PJ2", "PJ1", "PJ0", "PJ8", "PJ9";
				function = "lvds3";
				drive-strength = <30>;
			};

			lcd1_lvds2link_pins_b: lcd1_lvds2link@1 {
				pins = "PJ10", "PJ11", "PJ12", "PJ13", "PJ14", "PJ15", "PJ16", "PJ17", "PJ18", "PJ19", \
				"PJ7", "PJ6", "PJ5", "PJ4", "PJ3", "PJ2", "PJ1", "PJ0", "PJ8", "PJ9";
				function = "gpio_in";
			};

			lvds2link_pins_a: lvds2link@0 {
				pins = "PD0", "PD1", "PD2", "PD3", "PD4", "PD5", "PD8", "PD9", "PD6", "PD7", \
				"PD10", "PD11", "PD12", "PD13", "PD14", "PD15", "PD18", "PD19", "PD16", "PD17";
				function = "lvds2link";
				drive-strength = <30>;
			};
			lvds2link_pins_b: lvds2link@1 {
				pins = "PD0", "PD1", "PD2", "PD3", "PD4", "PD5", "PD8", "PD9", "PD6", "PD7", \
				"PD10", "PD11", "PD12", "PD13", "PD14", "PD15", "PD18", "PD19", "PD16", "PD17";
				function = "gpio_in";
			};

			rgb24_pins_a: rgb24@0 {
				pins = "PJ0", "PJ1", "PJ2", "PJ3", "PJ4", "PJ5", "PJ6", "PJ7", "PJ8", "PJ9", \
				"PJ10", "PJ11", "PJ12", "PJ13", "PJ14", "PJ15", "PJ16", "PJ17", "PJ18", "PJ19", \
				"PJ20", "PJ21", "PJ22", "PJ23", "PJ24", "PJ25", "PJ26", "PJ27";
				function = "rgb24";
				drive-strength = <30>;
			};
			rgb24_pins_b: rgb24@1 {
				pins = "PJ0", "PJ1", "PJ2", "PJ3", "PJ4", "PJ5", "PJ6", "PJ7", "PJ8", "PJ9", \
				"PJ10", "PJ11", "PJ12", "PJ13", "PJ14", "PJ15", "PJ16", "PJ17", "PJ18", "PJ19", \
				"PJ20", "PJ21", "PJ22", "PJ23", "PJ24", "PJ25", "PJ26", "PJ27";
				function = "gpio_in";
			};

			rgb18_pins_a: rgb18@0 {
				pins = "PD0", "PD1", "PD2", "PD3", "PD4", "PD5", "PD6", "PD7", "PD8", "PD9", \
				"PD10", "PD11", "PD12", "PD13", "PD14", "PD15", "PD16", "PD17", "PD18", "PD19", \
				"PD20", "PD21";
				function = "lcd0";
				drive-strength = <30>;
			};
			rgb18_pins_b: rgb18@1 {
				pins = "PD0", "PD1", "PD2", "PD3", "PD4", "PD5", "PD6", "PD7", "PD8", "PD9", \
				"PD10", "PD11", "PD12", "PD13", "PD14", "PD15", "PD16", "PD17", "PD18", "PD19", \
				"PD20", "PD21";
				function = "gpio_in";
			};

			eink_pins_a: eink@0 {
				pins = "PD0", "PD1", "PD2", "PD3", "PD4", "PD5", "PD6", "PD7", "PD8", "PD9", \
				"PD10", "PD11", "PD12", "PD13", "PD14", "PD15", "PD16", "PD17", "PD18", "PD19", \
				"PD20", "PD21", "PD22";
				function = "eink";
				drive-strength = <30>;
			};
			eink_pins_b: eink@1 {
				pins = "PD0", "PD1", "PD2", "PD3", "PD4", "PD5", "PD6", "PD7", "PD8", "PD9", \
				"PD10", "PD11", "PD12", "PD13", "PD14", "PD15", "PD16", "PD17", "PD18", "PD19", \
				"PD20", "PD21", "PD22";
				function = "gpio_in";
			};
			dsi4lane_pins_a: dsi4lane@0 {
				pins = "PD0", "PD1", "PD2", "PD3", "PD4", "PD5", "PD6", "PD7", "PD8", "PD9";
				function = "dsi0";
				drive-strength = <30>;
			};
			dsi4lane_pins_b: dsi4lane@1 {
				pins = "PD0", "PD1", "PD2", "PD3", "PD4", "PD5", "PD6", "PD7", "PD8", "PD9";
				function = "gpio_in";
			};
		};

		gpu: gpu@1800000 {
			device_type = "gpu";
			compatible = "img,gpu";
			reg = <0x0 0x01800000 0x0 0x80000>;
			interrupts = <GIC_SPI 97 IRQ_TYPE_LEVEL_HIGH>;
			interrupt-names = "IRQGPU";
			clocks = <&ccu CLK_PLL_GPU>, <&ccu CLK_GPU>, <&ccu CLK_BUS_GPU>;
			clock-names = "clk_parent", "clk_mali", "clk_bus";
			resets = <&ccu RST_BUS_GPU>;
			power-domains = <&pd_gpu>;
		};

		rfkill: rfkill {
			compatible = "allwinner,sunxi-rfkill";
			status = "disabled";
		};

		addr_mgt: addr_mgt {
			compatible = "allwinner,sunxi-addr_mgt";
			status = "disabled";
		};

		btlpm: btlpm {
			compatible = "allwinner,sunxi-btlpm";
			status = "disabled";
		};
	};
};
